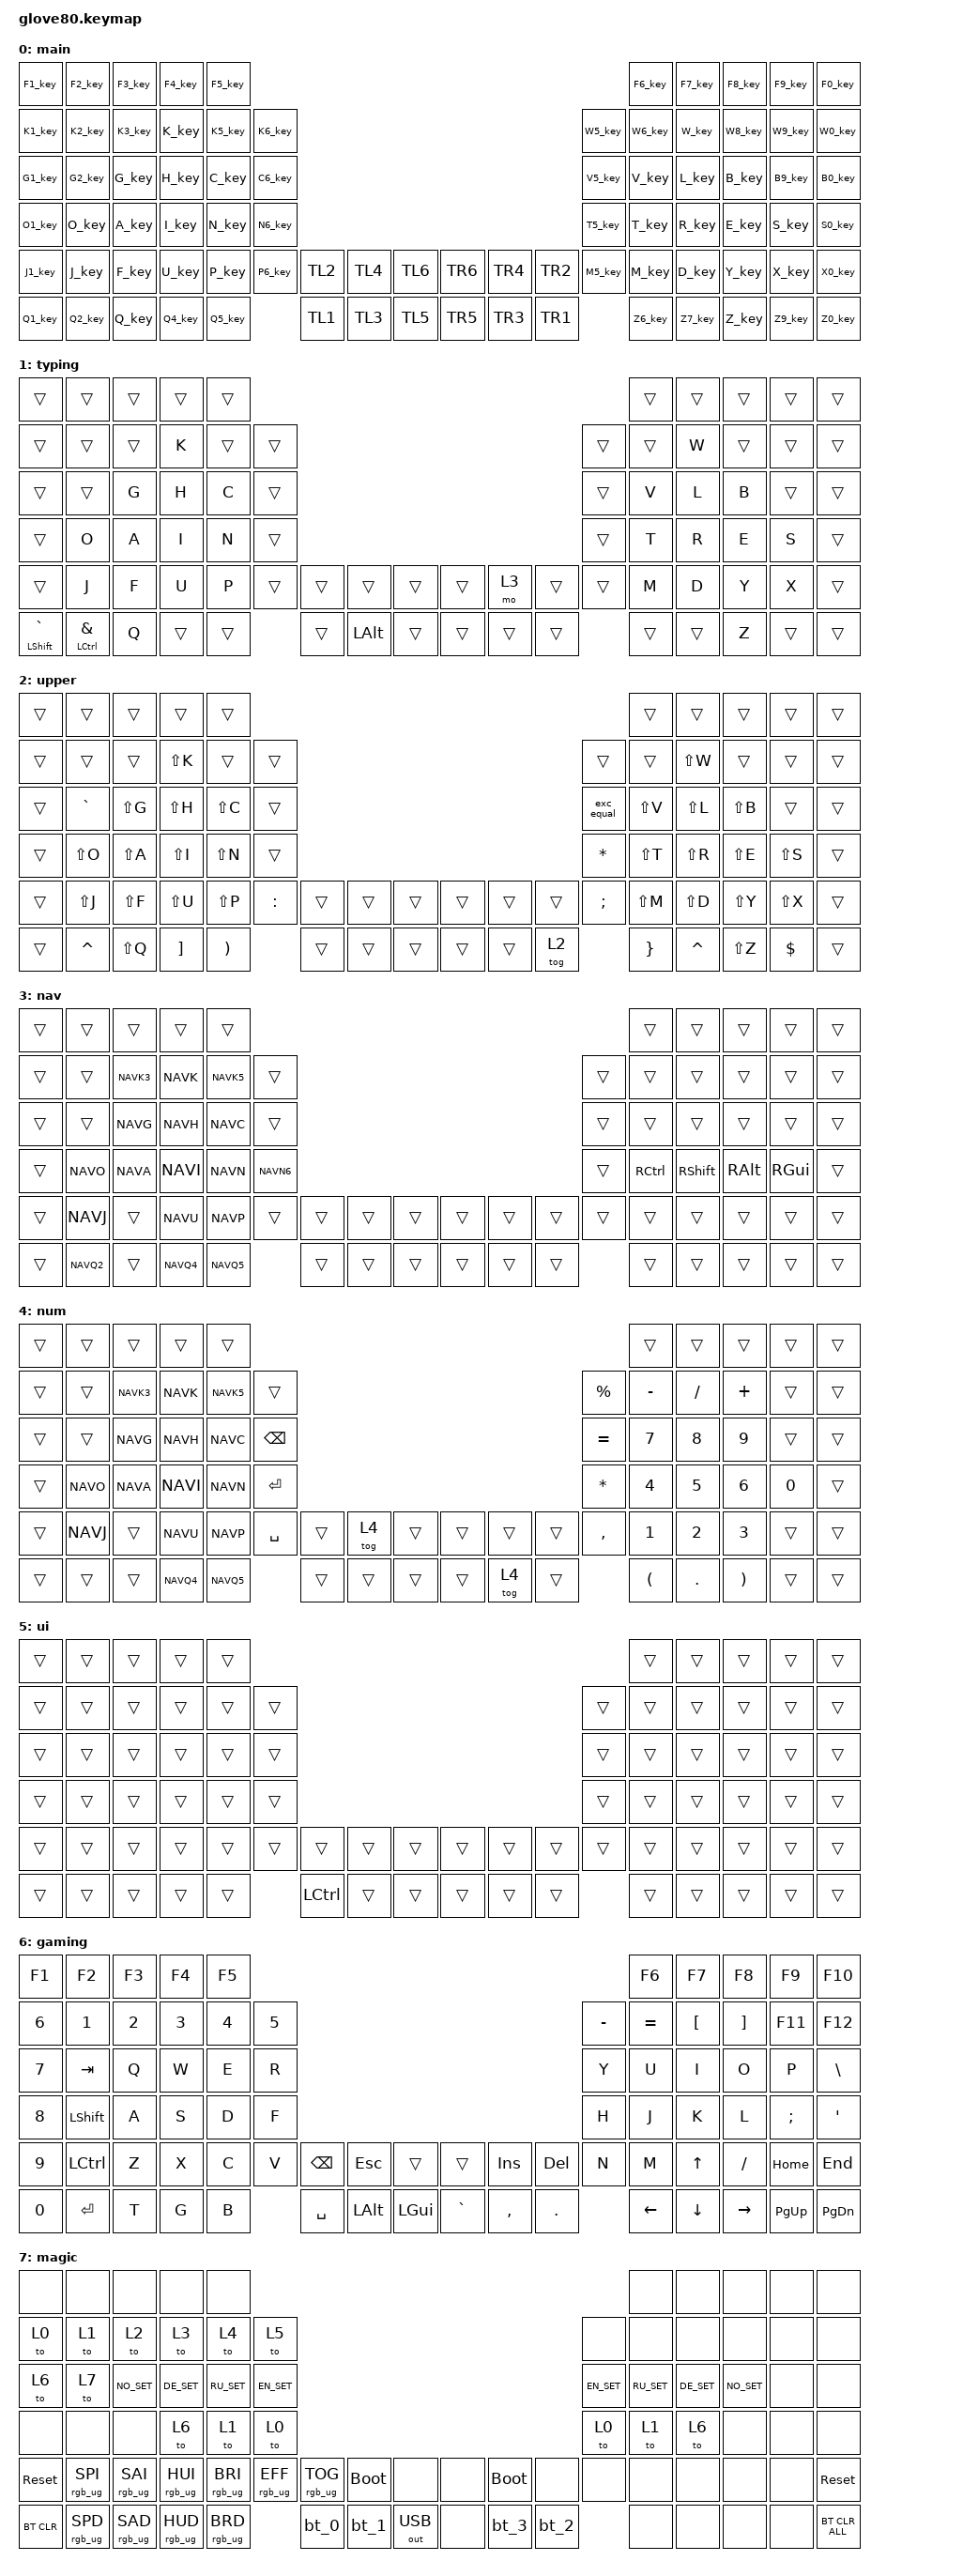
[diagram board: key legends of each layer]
/*
* Copyright (c) 2020 The ZMK Contributors
* Copyright (c) 2023 Innaworks Development Limited, trading as MoErgo
*
* SPDX-License-Identifier: MIT
*/
/* THIS FILE WAS GENERATED BY GLOVE80 LAYOUT EDITOR
*
* This file was generated automatically. You may or may not want to
* edit it directly.
*/

#include <behaviors.dtsi>
#include <dt-bindings/zmk/bt.h>
#include <dt-bindings/zmk/keys.h>
#include <dt-bindings/zmk/outputs.h>
#include <dt-bindings/zmk/rgb.h>

/* Automatically generated layer name #define */

#define Layer_Main 0
#define Layer_NAV 1
#define Layer_FUN 2
#define Layer_NUM 3
#define Layer_Magic 4

/ {
    macros {
        rgb_ug_status_macro: rgb_ug_status_macro {
            label = "RGB_UG_STATUS";
            compatible = "zmk,behavior-macro";
            #binding-cells = <0>;
            bindings = <&rgb_ug RGB_STATUS>;
        };
    };
};

/ {
    #ifdef BT_DISC_CMD

	behaviors {
		bt_0: bt_0 {
			compatible = "zmk,behavior-tap-dance";
			label = "BT_0";
			#binding-cells = <0>;
			tapping-term-ms = <200>;
			bindings = <&bt_select_0>, <&bt BT_DISC 0>;
		};

		bt_1: bt_1 {
			compatible = "zmk,behavior-tap-dance";
			label = "BT_1";
			#binding-cells = <0>;
			tapping-term-ms = <200>;
			bindings = <&bt_select_1>, <&bt BT_DISC 1>;
		};

		bt_2: bt_2 {
			compatible = "zmk,behavior-tap-dance";
			label = "BT_2";
			#binding-cells = <0>;
			tapping-term-ms = <200>;
			bindings = <&bt_select_2>, <&bt BT_DISC 2>;
		};

		bt_3: bt_3 {
			compatible = "zmk,behavior-tap-dance";
			label = "BT_3";
			#binding-cells = <0>;
			tapping-term-ms = <200>;
			bindings = <&bt_select_3>, <&bt BT_DISC 3>;
		};
	};

	macros {
		bt_select_0: bt_select_0 {
			label = "BT_SELECT_0";
			compatible = "zmk,behavior-macro";
			#binding-cells = <0>;
			bindings = <&out OUT_BLE &bt BT_SEL 0>;
		};

		bt_select_1: bt_select_1 {
			label = "BT_SELECT_1";
			compatible = "zmk,behavior-macro";
			#binding-cells = <0>;
			bindings = <&out OUT_BLE &bt BT_SEL 1>;
		};

		bt_select_2: bt_select_2 {
			label = "BT_SELECT_2";
			compatible = "zmk,behavior-macro";
			#binding-cells = <0>;
			bindings = <&out OUT_BLE &bt BT_SEL 2>;
		};

		bt_select_3: bt_select_3 {
			label = "BT_SELECT_3";
			compatible = "zmk,behavior-macro";
			#binding-cells = <0>;
			bindings = <&out OUT_BLE &bt BT_SEL 3>;
		};
	};

    #else

	macros {
		bt_0: bt_0 {
			label = "BT_0";
			compatible = "zmk,behavior-macro";
			#binding-cells = <0>;
			bindings = <&out OUT_BLE &bt BT_SEL 0>;
		};

		bt_1: bt_1 {
			label = "BT_1";
			compatible = "zmk,behavior-macro";
			#binding-cells = <0>;
			bindings = <&out OUT_BLE &bt BT_SEL 1>;
		};

		bt_2: bt_2 {
			label = "BT_2";
			compatible = "zmk,behavior-macro";
			#binding-cells = <0>;
			bindings = <&out OUT_BLE &bt BT_SEL 2>;
		};

		bt_3: bt_3 {
			label = "BT_3";
			compatible = "zmk,behavior-macro";
			#binding-cells = <0>;
			bindings = <&out OUT_BLE &bt BT_SEL 3>;
		};
	};

    #endif
};

&sk {
	release-after-ms = <900>;// release after 0.6s
	quick-release;// no double capitalization when rolling keys
};

&sl {
	ignore-modifiers;// allow chording sticky mods & layers

release-after-ms = <5000>;};

&lt {
	flavor = "balanced";
	tapping-term-ms = <200>;
	quick-tap-ms = <175>;
};


/ {
	behaviors {
		magic: magic {
			compatible = "zmk,behavior-hold-tap";
			label = "MAGIC_HOLD_TAP";
			#binding-cells = <2>;
			flavor = "tap-preferred";
			tapping-term-ms = <200>;
			bindings = <&mo>, <&rgb_ug_status_macro>;
		};

		lm: lm {
            compatible = "zmk,behavior-macro-two-param";
            wait-ms = <0>;
            tap-ms = <0>;
            #binding-cells = <2>;
            bindings = <&macro_param_1to1>,<&macro_press>,<&mo MACRO_PLACEHOLDER &macro_param_2to1>,<&macro_press>,<&kp MACRO_PLACEHOLDER>,<&macro_pause_for_release>,<&macro_param_2to1>,<&macro_release>,<&kp MACRO_PLACEHOLDER &macro_param_1to1>,<&macro_release>,<&mo MACRO_PLACEHOLDER>;
        };

		hml: hml {
			compatible = "zmk,behavior-hold-tap";
			#binding-cells = <2>;
			flavor = "balanced";
			tapping-term-ms = <270>;
			quick-tap-ms = <175>;
			require-prior-idle-ms = <150>;
			bindings = <&kp>, <&kp>;

			hold-trigger-key-positions = <28 29 30 31 32 40 41 42 43 44 58 59 60 61 62 75 76 77 78 79 69 70 71 72 73 74>;
			hold-trigger-on-release;
		};

		hmr: hmr {
			compatible = "zmk,behavior-hold-tap";
			#binding-cells = <2>;
			flavor = "balanced";
			tapping-term-ms = <280>;
			quick-tap-ms = <175>;
			require-prior-idle-ms = <350>;
			bindings = <&kp>, <&kp>;

			hold-trigger-key-positions = <27 26 25 24 23 39 38 37 36 35 51 50 49 48 47 68 67 66 65 64 15 14 13 12 11 10 69 70 71 72 73 74>;
			hold-trigger-on-release;
		};

		hlctrl:hlctrl {
			compatible = "zmk,behavior-hold-tap";
			#binding-cells = <2>;
			bindings = <&kp>, <&kp>;

			flavor = "tap-preferred";
			tapping-term-ms = <220>;
			quick-tap-ms = <220>;
			hold-trigger-key-positions = <0>;
		};



		swapper: swapper {
			compatible = "zmk,behavior-tri-state";
			#binding-cells = <0>;
			bindings = <&kp TAB>;
			ignored-key-positions = <25>;
		};

		copy_cut: copy_cut {
			compatible = "zmk,behavior-tap-dance";
			#binding-cells = <0>;
			tapping-term-ms = <200>;
			bindings = <&kp LC(INS)>, <&kp LC(X)>;
		};

		amp_ctrl:amp_ctrl { label = "amp_ctrl"; #binding-cells = <2>; compatible = "zmk,behavior-hold-tap";
            flavor = "balanced"; hold-trigger-on-release; tapping-term-ms = <150>; quick-tap-ms = <175>; require-prior-idle-ms = <0>; hold-trigger-key-positions = <0 1 2 3 4 10 11 12 22 23 34 46 13 24 25 26 35 36 37 38 47 48 49 50 66 14 15 27 39 51 64 65 67 68 5 6 7 8 9 19 20 21 32 33 45 63 18 29 30 31 41 42 43 44 59 60 61 62 77 16 17 28 40 58 75 76 79 80>;
            bindings = <&kp>, <&kp>;
        };

        grave_shft:grave_shft { label = "grave_shft"; #binding-cells = <2>; compatible = "zmk,behavior-hold-tap";
            flavor = "balanced"; hold-trigger-on-release; tapping-term-ms = <150>; quick-tap-ms = <175>; require-prior-idle-ms = <0>; hold-trigger-key-positions = <0 1 2 3 4 10 11 12 22 23 34 46 13 24 25 26 35 36 37 38 47 48 49 50 66 14 15 27 39 51 64 65 67 68 5 6 7 8 9 19 20 21 32 33 45 63 18 29 30 31 41 42 43 44 59 60 61 62 77 16 17 28 40 58 75 76 79 80>;
            bindings = <&kp>, <&kp>;
        };


/*<macros-start>*/

        reloadkeymap: reloadkeymap { label = "RELOADKEYMAP"; #binding-cells = <0>; compatible = "zmk,behavior-macro"; 
            wait-ms = <0>; tap-ms = <0>;
            bindings = <&kp LA(K) &kp TAB &kp TAB &kp SPACE &kp SPACE>;
        };

        cut_line: cut_line { label = "CUT_LINE"; #binding-cells = <0>; compatible = "zmk,behavior-macro"; 
            wait-ms = <0>; tap-ms = <0>;
            bindings = <&select_line &kp K_CUT &kp DELETE>;
        };

        move_down: move_down { label = "MOVE_DOWN"; #binding-cells = <0>; compatible = "zmk,behavior-macro"; 
            wait-ms = <0>; tap-ms = <0>;
            bindings = <&cut_line &kp DOWN &kp K_PASTE>;
        };

        move_up: move_up { label = "MOVE_UP"; #binding-cells = <0>; compatible = "zmk,behavior-macro"; 
            wait-ms = <0>; tap-ms = <0>;
            bindings = <&cut_line &kp UP_ARROW &kp K_PASTE>;
        };

        select_word: select_word { label = "SELECT_WORD"; #binding-cells = <0>; compatible = "zmk,behavior-macro"; 
            wait-ms = <0>; tap-ms = <0>;
            bindings = <&select_word_right>, <&select_word_left>;
        };

        select_line: select_line { label = "SELECT_LINE"; #binding-cells = <0>; compatible = "zmk,behavior-macro"; 
            wait-ms = <0>; tap-ms = <0>;
            bindings = <&kp HOME &kp LS(END)>;
        };

        delete_word: delete_word { label = "DELETE_WORD"; #binding-cells = <0>; compatible = "zmk,behavior-macro"; 
            wait-ms = <0>; tap-ms = <0>;
            bindings = <&select_word &kp BACKSPACE>;
        };

        delete_line: delete_line { label = "DELETE_LINE"; #binding-cells = <0>; compatible = "zmk,behavior-macro"; 
            wait-ms = <0>; tap-ms = <0>;
            bindings = <&select_line &kp BACKSPACE &kp BACKSPACE>;
        };

        copy_line: copy_line { label = "COPY_LINE"; #binding-cells = <0>; compatible = "zmk,behavior-macro"; 
            wait-ms = <0>; tap-ms = <0>;
            bindings = <&kp HOME &kp LS(END) &kp LC(C) &kp LC(RIGHT)>;
        };

        select_word_right: select_word_right { label = "SELECT_WORD_RIGHT"; #binding-cells = <0>; compatible = "zmk,behavior-macro"; 
            wait-ms = <0>; tap-ms = <0>;
            bindings = <&kp LC(RIGHT) &kp LC(LEFT) &kp LC(LS(RIGHT))>;
        };

        select_word_left: select_word_left { label = "SELECT_WORD_LEFT"; #binding-cells = <0>; compatible = "zmk,behavior-macro"; 
            wait-ms = <0>; tap-ms = <0>;
            bindings = <&kp LC(LEFT) &kp LC(RIGHT) &kp LC(LS(LEFT))>;
        };

        duplicate_line: duplicate_line { label = "DUPLICATE_LINE"; #binding-cells = <0>; compatible = "zmk,behavior-macro"; 
            wait-ms = <0>; tap-ms = <0>;
            bindings = <&kp HOME &kp LS(END) &kp LC(C) &kp RIGHT &kp ENTER &kp LC(V)>;
        };

        mo_ui: mo_ui { label = "MO_UI"; #binding-cells = <1>; compatible = "zmk,behavior-macro-one-param"; 
            wait-ms = <0>; tap-ms = <0>;
            bindings = <&macro_press>,<&mo 5 &macro_param_1to1>,<&macro_press>,<&kp MACRO_PLACEHOLDER>,<&macro_pause_for_release>,<&macro_param_1to1>,<&macro_release>,<&kp MACRO_PLACEHOLDER>,<&macro_release>,<&mo 5>,<&macro_press>;
        };

        exc_equal: exc_equal { label = "EXC_EQUAL"; #binding-cells = <0>; compatible = "zmk,behavior-macro"; 
            wait-ms = <0>; tap-ms = <0>;
            bindings = <&macro_tap>, <&kp EXCLAMATION>, <&kp EQUAL>;
        };

        grave_grave_grave: grave_grave_grave { label = "GRAVE_GRAVE_GRAVE"; #binding-cells = <0>; compatible = "zmk,behavior-macro"; 
            wait-ms = <0>; tap-ms = <0>;
            bindings = <&macro_tap>, <&kp GRAVE>, <&kp GRAVE>, <&kp GRAVE>;
        };
/*<macros-end>*/



/*<mods-start>*/

        H_key_hold_tap:H_key_hold_tap { label = "H_KEY_HOLD_TAP"; #binding-cells = <2>; compatible = "zmk,behavior-hold-tap";  
            flavor = "balanced"; hold-trigger-on-release; tapping-term-ms = <280>; quick-tap-ms = <175>; require-prior-idle-ms = <200>; hold-trigger-key-positions = <26 24 38>;
            bindings = <&mo_ui>, <&kp>;
        };

        A_key_hold_tap:A_key_hold_tap { label = "A_KEY_HOLD_TAP"; #binding-cells = <2>; compatible = "zmk,behavior-hold-tap";  
            flavor = "balanced"; hold-trigger-on-release; tapping-term-ms = <280>; quick-tap-ms = <175>; require-prior-idle-ms = <200>; hold-trigger-key-positions = <5 6 7 8 9 19 20 21 32 33 45 63 18 29 30 31 41 42 43 44 59 60 61 62 77 16 17 28 40 58 75 76 79 80>;
            bindings = <&kp>, <&kp>;
        };

        I_key_hold_tap:I_key_hold_tap { label = "I_KEY_HOLD_TAP"; #binding-cells = <2>; compatible = "zmk,behavior-hold-tap";  
            flavor = "balanced"; hold-trigger-on-release; tapping-term-ms = <280>; quick-tap-ms = <175>; require-prior-idle-ms = <200>; hold-trigger-key-positions = <24 26 36 38 48 50 18 5 6 7 8 9 19 20 21 32 33 45 63 18 29 30 31 41 42 43 44 59 60 61 62 77 16 17 28 40 58 75 76 79 80>;
            bindings = <&kp>, <&kp>;
        };

        N_key_hold_tap:N_key_hold_tap { label = "N_KEY_HOLD_TAP"; #binding-cells = <2>; compatible = "zmk,behavior-hold-tap";  
            flavor = "balanced"; hold-trigger-on-release; tapping-term-ms = <280>; quick-tap-ms = <175>; require-prior-idle-ms = <200>; hold-trigger-key-positions = <0 1 2 3 4 10 11 12 22 23 34 46 13 24 25 26 35 36 37 38 47 48 49 50 66 14 15 27 39 51 64 65 67 68 5 6 7 8 9 19 20 21 32 33 45 63 18 29 30 31 41 42 43 44 59 60 61 62 77 16 17 28 40 58 75 76 79 80>;
            bindings = <&kp>, <&kp>;
        };

        F_key_hold_tap:F_key_hold_tap { label = "F_KEY_HOLD_TAP"; #binding-cells = <2>; compatible = "zmk,behavior-hold-tap";  
            flavor = "balanced"; hold-trigger-on-release; tapping-term-ms = <280>; quick-tap-ms = <175>; require-prior-idle-ms = <200>; hold-trigger-key-positions = <25 26 50 38 5 6 7 8 9 19 20 21 32 33 45 63 18 29 30 31 41 42 43 44 59 60 61 62 77 16 17 28 40 58 75 76 79 80>;
            bindings = <&mo>, <&kp>;
        };

        grave_x_gra_gra_gra:grave_x_gra_gra_gra { label = "GRAVE_X_GRA_GRA_GRA"; #binding-cells = <2>; compatible = "zmk,behavior-hold-tap";  
            flavor = "balanced"; hold-trigger-on-release; tapping-term-ms = <250>; quick-tap-ms = <175>; require-prior-idle-ms = <0>; hold-trigger-key-positions = <0 1 2 3 4 10 11 12 22 23 34 46 13 24 25 26 35 36 37 38 47 48 49 50 66 14 15 27 39 51 64 65 67 68 5 6 7 8 9 19 20 21 32 33 45 63 18 29 30 31 41 42 43 44 59 60 61 62 77 16 17 28 40 58 75 76 79 80>;
            bindings = <&grave_grave_grave>, <&kp>;
        };

        lef_bra_x_rig_bra:lef_bra_x_rig_bra { label = "LEF_BRA_X_RIG_BRA"; #binding-cells = <2>; compatible = "zmk,behavior-hold-tap";  
            flavor = "balanced"; hold-trigger-on-release; tapping-term-ms = <250>; quick-tap-ms = <175>; require-prior-idle-ms = <0>; hold-trigger-key-positions = <0 1 2 3 4 10 11 12 22 23 34 46 13 24 25 26 35 36 37 38 47 48 49 50 66 14 15 27 39 51 64 65 67 68 5 6 7 8 9 19 20 21 32 33 45 63 18 29 30 31 41 42 43 44 59 60 61 62 77 16 17 28 40 58 75 76 79 80>;
            bindings = <&kp>, <&kp>;
        };

        lef_par_x_rig_par:lef_par_x_rig_par { label = "LEF_PAR_X_RIG_PAR"; #binding-cells = <2>; compatible = "zmk,behavior-hold-tap";  
            flavor = "balanced"; hold-trigger-on-release; tapping-term-ms = <250>; quick-tap-ms = <175>; require-prior-idle-ms = <0>; hold-trigger-key-positions = <0 1 2 3 4 10 11 12 22 23 34 46 13 24 25 26 35 36 37 38 47 48 49 50 66 14 15 27 39 51 64 65 67 68 5 6 7 8 9 19 20 21 32 33 45 63 18 29 30 31 41 42 43 44 59 60 61 62 77 16 17 28 40 58 75 76 79 80>;
            bindings = <&kp>, <&kp>;
        };

        T_key_hold_tap:T_key_hold_tap { label = "T_KEY_HOLD_TAP"; #binding-cells = <2>; compatible = "zmk,behavior-hold-tap";  
            flavor = "balanced"; hold-trigger-on-release; tapping-term-ms = <280>; quick-tap-ms = <175>; require-prior-idle-ms = <200>; hold-trigger-key-positions = <0 1 2 3 4 10 11 12 22 23 34 46 13 24 25 26 35 36 37 38 47 48 49 50 66 14 15 27 39 51 64 65 67 68 5 6 7 8 9 19 20 21 32 33 45 63 18 29 30 31 41 42 43 44 59 60 61 62 77 16 17 28 40 58 75 76 79 80>;
            bindings = <&kp>, <&kp>;
        };

        R_key_hold_tap:R_key_hold_tap { label = "R_KEY_HOLD_TAP"; #binding-cells = <2>; compatible = "zmk,behavior-hold-tap";  
            flavor = "balanced"; hold-trigger-on-release; tapping-term-ms = <280>; quick-tap-ms = <175>; require-prior-idle-ms = <200>; hold-trigger-key-positions = <0 1 2 3 4 10 11 12 22 23 34 46 13 24 25 26 35 36 37 38 47 48 49 50 66 14 15 27 39 51 64 65 67 68>;
            bindings = <&kp>, <&kp>;
        };

        E_key_hold_tap:E_key_hold_tap { label = "E_KEY_HOLD_TAP"; #binding-cells = <2>; compatible = "zmk,behavior-hold-tap";  
            flavor = "balanced"; hold-trigger-on-release; tapping-term-ms = <280>; quick-tap-ms = <175>; require-prior-idle-ms = <200>; hold-trigger-key-positions = <0 1 2 3 4 10 11 12 22 23 34 46 13 24 25 26 35 36 37 38 47 48 49 50 66 14 15 27 39 51 64 65 67 68>;
            bindings = <&kp>, <&kp>;
        };

        left_brace_x_rig_bra:left_brace_x_rig_bra { label = "LEFT_BRACE_X_RIG_BRA"; #binding-cells = <2>; compatible = "zmk,behavior-hold-tap";  
            flavor = "balanced"; hold-trigger-on-release; tapping-term-ms = <280>; quick-tap-ms = <175>; require-prior-idle-ms = <0>; hold-trigger-key-positions = <0 1 2 3 4 10 11 12 22 23 34 46 13 24 25 26 35 36 37 38 47 48 49 50 66 14 15 27 39 51 64 65 67 68 5 6 7 8 9 19 20 21 32 33 45 63 18 29 30 31 41 42 43 44 59 60 61 62 77 16 17 28 40 58 75 76 79 80>;
            bindings = <&kp>, <&kp>;
        };

        EN_SET:EN_SET { label = "EN_SET"; compatible = "zmk,behavior-mod-morph"; #binding-cells = <0>;
            bindings = <&kp LG(F10)>, <&kp LG(F10)>;
            mods = <(MOD_LALT|MOD_LCTL|MOD_LGUI|MOD_LSFT|MOD_RALT|MOD_RCTL|MOD_RGUI|MOD_RSFT)>;
            keep-mods = <(MOD_LALT|MOD_LCTL|MOD_LGUI|MOD_LSFT|MOD_RALT|MOD_RCTL|MOD_RGUI|MOD_RSFT)>;
        };

        RU_SET:RU_SET { label = "RU_SET"; compatible = "zmk,behavior-mod-morph"; #binding-cells = <0>;
            bindings = <&kp LG(F11)>, <&kp LG(F11)>;
            mods = <(MOD_LALT|MOD_LCTL|MOD_LGUI|MOD_LSFT|MOD_RALT|MOD_RCTL|MOD_RGUI|MOD_RSFT)>;
            keep-mods = <(MOD_LALT|MOD_LCTL|MOD_LGUI|MOD_LSFT|MOD_RALT|MOD_RCTL|MOD_RGUI|MOD_RSFT)>;
        };

        DE_SET:DE_SET { label = "DE_SET"; compatible = "zmk,behavior-mod-morph"; #binding-cells = <0>;
            bindings = <&kp LG(F12)>, <&kp LG(F12)>;
            mods = <(MOD_LALT|MOD_LCTL|MOD_LGUI|MOD_LSFT|MOD_RALT|MOD_RCTL|MOD_RGUI|MOD_RSFT)>;
            keep-mods = <(MOD_LALT|MOD_LCTL|MOD_LGUI|MOD_LSFT|MOD_RALT|MOD_RCTL|MOD_RGUI|MOD_RSFT)>;
        };

        NO_SET:NO_SET { label = "NO_SET"; compatible = "zmk,behavior-mod-morph"; #binding-cells = <0>;
            bindings = <&kp LG(F13)>, <&kp LG(F13)>;
            mods = <(MOD_LALT|MOD_LCTL|MOD_LGUI|MOD_LSFT|MOD_RALT|MOD_RCTL|MOD_RGUI|MOD_RSFT)>;
            keep-mods = <(MOD_LALT|MOD_LCTL|MOD_LGUI|MOD_LSFT|MOD_RALT|MOD_RCTL|MOD_RGUI|MOD_RSFT)>;
        };

        NAVK3:NAVK3 { label = "NAVK3"; compatible = "zmk,behavior-mod-morph"; #binding-cells = <0>;
            bindings = <&none>, <&none>;
            mods = <(MOD_LALT|MOD_LCTL|MOD_LGUI|MOD_LSFT|MOD_RALT|MOD_RCTL|MOD_RGUI|MOD_RSFT)>;
            keep-mods = <(MOD_LALT|MOD_LCTL|MOD_LGUI|MOD_LSFT|MOD_RALT|MOD_RCTL|MOD_RGUI|MOD_RSFT)>;
        };

        NAVK:NAVK { label = "NAVK"; compatible = "zmk,behavior-mod-morph"; #binding-cells = <0>;
            bindings = <&kp PAGE_UP>, <&kp PAGE_UP>;
            mods = <(MOD_LALT|MOD_LCTL|MOD_LGUI|MOD_LSFT|MOD_RALT|MOD_RCTL|MOD_RGUI|MOD_RSFT)>;
            keep-mods = <(MOD_LALT|MOD_LCTL|MOD_LGUI|MOD_LSFT|MOD_RALT|MOD_RCTL|MOD_RGUI|MOD_RSFT)>;
        };

        NAVK5:NAVK5 { label = "NAVK5"; compatible = "zmk,behavior-mod-morph"; #binding-cells = <0>;
            bindings = <&kp PAGE_DOWN>, <&kp PAGE_DOWN>;
            mods = <(MOD_LALT|MOD_LCTL|MOD_LGUI|MOD_LSFT|MOD_RALT|MOD_RCTL|MOD_RGUI|MOD_RSFT)>;
            keep-mods = <(MOD_LALT|MOD_LCTL|MOD_LGUI|MOD_LSFT|MOD_RALT|MOD_RCTL|MOD_RGUI|MOD_RSFT)>;
        };

        NAVG:NAVG { label = "NAVG"; compatible = "zmk,behavior-mod-morph"; #binding-cells = <0>;
            bindings = <&none>, <&none>;
            mods = <(MOD_LALT|MOD_LCTL|MOD_LGUI|MOD_LSFT|MOD_RALT|MOD_RCTL|MOD_RGUI|MOD_RSFT)>;
            keep-mods = <(MOD_LALT|MOD_LCTL|MOD_LGUI|MOD_LSFT|MOD_RALT|MOD_RCTL|MOD_RGUI|MOD_RSFT)>;
        };

        NAVH:NAVH { label = "NAVH"; compatible = "zmk,behavior-mod-morph"; #binding-cells = <0>;
            bindings = <&kp HOME>, <&kp HOME>;
            mods = <(MOD_LALT|MOD_LCTL|MOD_LGUI|MOD_LSFT|MOD_RALT|MOD_RCTL|MOD_RGUI|MOD_RSFT)>;
            keep-mods = <(MOD_LALT|MOD_LCTL|MOD_LGUI|MOD_LSFT|MOD_RALT|MOD_RCTL|MOD_RGUI|MOD_RSFT)>;
        };

        NAVC:NAVC { label = "NAVC"; compatible = "zmk,behavior-mod-morph"; #binding-cells = <0>;
            bindings = <&kp END>, <&kp END>;
            mods = <(MOD_LALT|MOD_LCTL|MOD_LGUI|MOD_LSFT|MOD_RALT|MOD_RCTL|MOD_RGUI|MOD_RSFT)>;
            keep-mods = <(MOD_LALT|MOD_LCTL|MOD_LGUI|MOD_LSFT|MOD_RALT|MOD_RCTL|MOD_RGUI|MOD_RSFT)>;
        };

        NAVO:NAVO { label = "NAVO"; compatible = "zmk,behavior-mod-morph"; #binding-cells = <0>;
            bindings = <&kp LSHIFT>, <&kp LSHIFT>;
            mods = <(MOD_LALT|MOD_LCTL|MOD_LGUI|MOD_LSFT|MOD_RALT|MOD_RCTL|MOD_RGUI|MOD_RSFT)>;
            keep-mods = <(MOD_LALT|MOD_LCTL|MOD_LGUI|MOD_LSFT|MOD_RALT|MOD_RCTL|MOD_RGUI|MOD_RSFT)>;
        };

        NAVA:NAVA { label = "NAVA"; compatible = "zmk,behavior-mod-morph"; #binding-cells = <0>;
            bindings = <&none>, <&none>;
            mods = <(MOD_LALT|MOD_LCTL|MOD_LGUI|MOD_LSFT|MOD_RALT|MOD_RCTL|MOD_RGUI|MOD_RSFT)>;
            keep-mods = <(MOD_LALT|MOD_LCTL|MOD_LGUI|MOD_LSFT|MOD_RALT|MOD_RCTL|MOD_RGUI|MOD_RSFT)>;
        };

        NAVI:NAVI { label = "NAVI"; compatible = "zmk,behavior-mod-morph"; #binding-cells = <0>;
            bindings = <&kp LC(LEFT)>, <&kp LC(LEFT)>;
            mods = <(MOD_LALT|MOD_LCTL|MOD_LGUI|MOD_LSFT|MOD_RALT|MOD_RCTL|MOD_RGUI|MOD_RSFT)>;
            keep-mods = <(MOD_LALT|MOD_LCTL|MOD_LGUI|MOD_LSFT|MOD_RALT|MOD_RCTL|MOD_RGUI|MOD_RSFT)>;
        };

        NAVN:NAVN { label = "NAVN"; compatible = "zmk,behavior-mod-morph"; #binding-cells = <0>;
            bindings = <&kp LC(RIGHT)>, <&kp LC(RIGHT)>;
            mods = <(MOD_LALT|MOD_LCTL|MOD_LGUI|MOD_LSFT|MOD_RALT|MOD_RCTL|MOD_RGUI|MOD_RSFT)>;
            keep-mods = <(MOD_LALT|MOD_LCTL|MOD_LGUI|MOD_LSFT|MOD_RALT|MOD_RCTL|MOD_RGUI|MOD_RSFT)>;
        };

        NAVN6:NAVN6 { label = "NAVN6"; compatible = "zmk,behavior-mod-morph"; #binding-cells = <0>;
            bindings = <&kp TAB>, <&kp TAB>;
            mods = <(MOD_LALT|MOD_LCTL|MOD_LGUI|MOD_LSFT|MOD_RALT|MOD_RCTL|MOD_RGUI|MOD_RSFT)>;
            keep-mods = <(MOD_LALT|MOD_LCTL|MOD_LGUI|MOD_LSFT|MOD_RALT|MOD_RCTL|MOD_RGUI|MOD_RSFT)>;
        };

        NAVJ:NAVJ { label = "NAVJ"; compatible = "zmk,behavior-mod-morph"; #binding-cells = <0>;
            bindings = <&kp LCTRL>, <&kp LCTRL>;
            mods = <(MOD_LALT|MOD_LCTL|MOD_LGUI|MOD_LSFT|MOD_RALT|MOD_RCTL|MOD_RGUI|MOD_RSFT)>;
            keep-mods = <(MOD_LALT|MOD_LCTL|MOD_LGUI|MOD_LSFT|MOD_RALT|MOD_RCTL|MOD_RGUI|MOD_RSFT)>;
        };

        NAVU:NAVU { label = "NAVU"; compatible = "zmk,behavior-mod-morph"; #binding-cells = <0>;
            bindings = <&kp UP>, <&kp UP>;
            mods = <(MOD_LALT|MOD_LCTL|MOD_LGUI|MOD_LSFT|MOD_RALT|MOD_RCTL|MOD_RGUI|MOD_RSFT)>;
            keep-mods = <(MOD_LALT|MOD_LCTL|MOD_LGUI|MOD_LSFT|MOD_RALT|MOD_RCTL|MOD_RGUI|MOD_RSFT)>;
        };

        NAVP:NAVP { label = "NAVP"; compatible = "zmk,behavior-mod-morph"; #binding-cells = <0>;
            bindings = <&kp DOWN>, <&kp DOWN>;
            mods = <(MOD_LALT|MOD_LCTL|MOD_LGUI|MOD_LSFT|MOD_RALT|MOD_RCTL|MOD_RGUI|MOD_RSFT)>;
            keep-mods = <(MOD_LALT|MOD_LCTL|MOD_LGUI|MOD_LSFT|MOD_RALT|MOD_RCTL|MOD_RGUI|MOD_RSFT)>;
        };

        NAVQ2:NAVQ2 { label = "NAVQ2"; compatible = "zmk,behavior-mod-morph"; #binding-cells = <0>;
            bindings = <&kp DELETE>, <&kp DELETE>;
            mods = <(MOD_LALT|MOD_LCTL|MOD_LGUI|MOD_LSFT|MOD_RALT|MOD_RCTL|MOD_RGUI|MOD_RSFT)>;
            keep-mods = <(MOD_LALT|MOD_LCTL|MOD_LGUI|MOD_LSFT|MOD_RALT|MOD_RCTL|MOD_RGUI|MOD_RSFT)>;
        };

        NAVQ4:NAVQ4 { label = "NAVQ4"; compatible = "zmk,behavior-mod-morph"; #binding-cells = <0>;
            bindings = <&kp LEFT>, <&kp LEFT>;
            mods = <(MOD_LALT|MOD_LCTL|MOD_LGUI|MOD_LSFT|MOD_RALT|MOD_RCTL|MOD_RGUI|MOD_RSFT)>;
            keep-mods = <(MOD_LALT|MOD_LCTL|MOD_LGUI|MOD_LSFT|MOD_RALT|MOD_RCTL|MOD_RGUI|MOD_RSFT)>;
        };

        NAVQ5:NAVQ5 { label = "NAVQ5"; compatible = "zmk,behavior-mod-morph"; #binding-cells = <0>;
            bindings = <&kp RIGHT>, <&kp RIGHT>;
            mods = <(MOD_LALT|MOD_LCTL|MOD_LGUI|MOD_LSFT|MOD_RALT|MOD_RCTL|MOD_RGUI|MOD_RSFT)>;
            keep-mods = <(MOD_LALT|MOD_LCTL|MOD_LGUI|MOD_LSFT|MOD_RALT|MOD_RCTL|MOD_RGUI|MOD_RSFT)>;
        };

        F1_key:F1_key { label = "F1_KEY"; compatible = "zmk,behavior-mod-morph"; #binding-cells = <0>;
            bindings = <&kp F1>, <&kp F1>;
            mods = <(MOD_LALT|MOD_LCTL|MOD_LGUI|MOD_LSFT|MOD_RALT|MOD_RCTL|MOD_RGUI|MOD_RSFT)>;
            keep-mods = <(MOD_LALT|MOD_LCTL|MOD_LGUI|MOD_LSFT|MOD_RALT|MOD_RCTL|MOD_RGUI|MOD_RSFT)>;
        };

        F2_key:F2_key { label = "F2_KEY"; compatible = "zmk,behavior-mod-morph"; #binding-cells = <0>;
            bindings = <&kp F2>, <&kp F2>;
            mods = <(MOD_LALT|MOD_LCTL|MOD_LGUI|MOD_LSFT|MOD_RALT|MOD_RCTL|MOD_RGUI|MOD_RSFT)>;
            keep-mods = <(MOD_LALT|MOD_LCTL|MOD_LGUI|MOD_LSFT|MOD_RALT|MOD_RCTL|MOD_RGUI|MOD_RSFT)>;
        };

        F3_key:F3_key { label = "F3_KEY"; compatible = "zmk,behavior-mod-morph"; #binding-cells = <0>;
            bindings = <&kp F3>, <&kp F3>;
            mods = <(MOD_LALT|MOD_LCTL|MOD_LGUI|MOD_LSFT|MOD_RALT|MOD_RCTL|MOD_RGUI|MOD_RSFT)>;
            keep-mods = <(MOD_LALT|MOD_LCTL|MOD_LGUI|MOD_LSFT|MOD_RALT|MOD_RCTL|MOD_RGUI|MOD_RSFT)>;
        };

        F4_key:F4_key { label = "F4_KEY"; compatible = "zmk,behavior-mod-morph"; #binding-cells = <0>;
            bindings = <&kp F4>, <&kp F4>;
            mods = <(MOD_LALT|MOD_LCTL|MOD_LGUI|MOD_LSFT|MOD_RALT|MOD_RCTL|MOD_RGUI|MOD_RSFT)>;
            keep-mods = <(MOD_LALT|MOD_LCTL|MOD_LGUI|MOD_LSFT|MOD_RALT|MOD_RCTL|MOD_RGUI|MOD_RSFT)>;
        };

        F5_key:F5_key { label = "F5_KEY"; compatible = "zmk,behavior-mod-morph"; #binding-cells = <0>;
            bindings = <&kp F5>, <&kp F5>;
            mods = <(MOD_LALT|MOD_LCTL|MOD_LGUI|MOD_LSFT|MOD_RALT|MOD_RCTL|MOD_RGUI|MOD_RSFT)>;
            keep-mods = <(MOD_LALT|MOD_LCTL|MOD_LGUI|MOD_LSFT|MOD_RALT|MOD_RCTL|MOD_RGUI|MOD_RSFT)>;
        };

        K1_key:K1_key { label = "K1_KEY"; compatible = "zmk,behavior-mod-morph"; #binding-cells = <0>;
            bindings = <&kp F11>, <&kp F11>;
            mods = <(MOD_LALT|MOD_LCTL|MOD_LGUI|MOD_LSFT|MOD_RALT|MOD_RCTL|MOD_RGUI|MOD_RSFT)>;
            keep-mods = <(MOD_LALT|MOD_LCTL|MOD_LGUI|MOD_LSFT|MOD_RALT|MOD_RCTL|MOD_RGUI|MOD_RSFT)>;
        };

        K2_key:K2_key { label = "K2_KEY"; compatible = "zmk,behavior-mod-morph"; #binding-cells = <0>;
            bindings = <&kp F12>, <&kp F12>;
            mods = <(MOD_LALT|MOD_LCTL|MOD_LGUI|MOD_LSFT|MOD_RALT|MOD_RCTL|MOD_RGUI|MOD_RSFT)>;
            keep-mods = <(MOD_LALT|MOD_LCTL|MOD_LGUI|MOD_LSFT|MOD_RALT|MOD_RCTL|MOD_RGUI|MOD_RSFT)>;
        };

        G1_key:G1_key { label = "G1_KEY"; compatible = "zmk,behavior-mod-morph"; #binding-cells = <0>;
            bindings = <&G1_key_lshift_link>, <&G1_key_rshift_sink>;
            mods = <(MOD_RSFT)>;
            
        };

        G1_key_lshift_link:G1_key_lshift_link { label = "G1_KEY_LSHIFT_LINK"; compatible = "zmk,behavior-mod-morph"; #binding-cells = <0>;
            bindings = <&kp DOLLAR>, <&G1_key_lshift_sink>;
            mods = <(MOD_LSFT)>;
            
        };

        G1_key_lshift_sink:G1_key_lshift_sink { label = "G1_KEY_LSHIFT_SINK"; compatible = "zmk,behavior-mod-morph"; #binding-cells = <0>;
            bindings = <&kp LA(F13)>, <&kp DOLLAR>;
            mods = <(MOD_LALT|MOD_LCTL|MOD_LGUI|MOD_RALT|MOD_RCTL|MOD_RGUI|MOD_RSFT)>;
            keep-mods = <(MOD_LALT|MOD_LCTL|MOD_LGUI|MOD_RALT|MOD_RCTL|MOD_RGUI|MOD_RSFT)>;
        };

        G1_key_rshift_sink:G1_key_rshift_sink { label = "G1_KEY_RSHIFT_SINK"; compatible = "zmk,behavior-mod-morph"; #binding-cells = <0>;
            bindings = <&kp RA(F13)>, <&kp DOLLAR>;
            mods = <(MOD_LALT|MOD_LCTL|MOD_LGUI|MOD_LSFT|MOD_RALT|MOD_RCTL|MOD_RGUI)>;
            keep-mods = <(MOD_LALT|MOD_LCTL|MOD_LGUI|MOD_LSFT|MOD_RALT|MOD_RCTL|MOD_RGUI)>;
        };

        G2_key:G2_key { label = "G2_KEY"; compatible = "zmk,behavior-mod-morph"; #binding-cells = <0>;
            bindings = <&G2_key_lshift_link>, <&G2_key_rshift_sink>;
            mods = <(MOD_RSFT)>;
            
        };

        G2_key_lshift_link:G2_key_lshift_link { label = "G2_KEY_LSHIFT_LINK"; compatible = "zmk,behavior-mod-morph"; #binding-cells = <0>;
            bindings = <&kp HASH>, <&G2_key_lshift_sink>;
            mods = <(MOD_LSFT)>;
            
        };

        G2_key_lshift_sink:G2_key_lshift_sink { label = "G2_KEY_LSHIFT_SINK"; compatible = "zmk,behavior-mod-morph"; #binding-cells = <0>;
            bindings = <&kp LA(F14)>, <&kp HASH>;
            mods = <(MOD_LALT|MOD_LCTL|MOD_LGUI|MOD_RALT|MOD_RCTL|MOD_RGUI|MOD_RSFT)>;
            keep-mods = <(MOD_LALT|MOD_LCTL|MOD_LGUI|MOD_RALT|MOD_RCTL|MOD_RGUI|MOD_RSFT)>;
        };

        G2_key_rshift_sink:G2_key_rshift_sink { label = "G2_KEY_RSHIFT_SINK"; compatible = "zmk,behavior-mod-morph"; #binding-cells = <0>;
            bindings = <&kp RA(F14)>, <&kp HASH>;
            mods = <(MOD_LALT|MOD_LCTL|MOD_LGUI|MOD_LSFT|MOD_RALT|MOD_RCTL|MOD_RGUI)>;
            keep-mods = <(MOD_LALT|MOD_LCTL|MOD_LGUI|MOD_LSFT|MOD_RALT|MOD_RCTL|MOD_RGUI)>;
        };

        O1_key:O1_key { label = "O1_KEY"; compatible = "zmk,behavior-mod-morph"; #binding-cells = <0>;
            bindings = <&O1_key_lshift_link>, <&O1_key_rshift_sink>;
            mods = <(MOD_RSFT)>;
            
        };

        O1_key_lshift_link:O1_key_lshift_link { label = "O1_KEY_LSHIFT_LINK"; compatible = "zmk,behavior-mod-morph"; #binding-cells = <0>;
            bindings = <&kp DOUBLE_QUOTES>, <&O1_key_lshift_sink>;
            mods = <(MOD_LSFT)>;
            
        };

        O1_key_lshift_sink:O1_key_lshift_sink { label = "O1_KEY_LSHIFT_SINK"; compatible = "zmk,behavior-mod-morph"; #binding-cells = <0>;
            bindings = <&kp LA(F15)>, <&kp DOUBLE_QUOTES>;
            mods = <(MOD_LALT|MOD_LCTL|MOD_LGUI|MOD_RALT|MOD_RCTL|MOD_RGUI|MOD_RSFT)>;
            keep-mods = <(MOD_LALT|MOD_LCTL|MOD_LGUI|MOD_RALT|MOD_RCTL|MOD_RGUI|MOD_RSFT)>;
        };

        O1_key_rshift_sink:O1_key_rshift_sink { label = "O1_KEY_RSHIFT_SINK"; compatible = "zmk,behavior-mod-morph"; #binding-cells = <0>;
            bindings = <&kp RA(F15)>, <&kp DOUBLE_QUOTES>;
            mods = <(MOD_LALT|MOD_LCTL|MOD_LGUI|MOD_LSFT|MOD_RALT|MOD_RCTL|MOD_RGUI)>;
            keep-mods = <(MOD_LALT|MOD_LCTL|MOD_LGUI|MOD_LSFT|MOD_RALT|MOD_RCTL|MOD_RGUI)>;
        };

        J1_key:J1_key { label = "J1_KEY"; compatible = "zmk,behavior-mod-morph"; #binding-cells = <0>;
            bindings = <&J1_key_lshift_link>, <&J1_key_rshift_sink>;
            mods = <(MOD_RSFT)>;
            
        };

        J1_key_lshift_link:J1_key_lshift_link { label = "J1_KEY_LSHIFT_LINK"; compatible = "zmk,behavior-mod-morph"; #binding-cells = <0>;
            bindings = <&kp SINGLE_QUOTE>, <&J1_key_lshift_sink>;
            mods = <(MOD_LSFT)>;
            
        };

        J1_key_lshift_sink:J1_key_lshift_sink { label = "J1_KEY_LSHIFT_SINK"; compatible = "zmk,behavior-mod-morph"; #binding-cells = <0>;
            bindings = <&kp LA(F16)>, <&kp SINGLE_QUOTE>;
            mods = <(MOD_LALT|MOD_LCTL|MOD_LGUI|MOD_RALT|MOD_RCTL|MOD_RGUI|MOD_RSFT)>;
            keep-mods = <(MOD_LALT|MOD_LCTL|MOD_LGUI|MOD_RALT|MOD_RCTL|MOD_RGUI|MOD_RSFT)>;
        };

        J1_key_rshift_sink:J1_key_rshift_sink { label = "J1_KEY_RSHIFT_SINK"; compatible = "zmk,behavior-mod-morph"; #binding-cells = <0>;
            bindings = <&kp RA(F16)>, <&kp SINGLE_QUOTE>;
            mods = <(MOD_LALT|MOD_LCTL|MOD_LGUI|MOD_LSFT|MOD_RALT|MOD_RCTL|MOD_RGUI)>;
            keep-mods = <(MOD_LALT|MOD_LCTL|MOD_LGUI|MOD_LSFT|MOD_RALT|MOD_RCTL|MOD_RGUI)>;
        };

        K_key:K_key { label = "K_KEY"; compatible = "zmk,behavior-mod-morph"; #binding-cells = <0>;
            bindings = <&K_key_rshift_link>, <&K_key_lctrl_sink>;
            mods = <(MOD_LCTL)>;
            
        };

        K_key_lshift_link:K_key_lshift_link { label = "K_KEY_LSHIFT_LINK"; compatible = "zmk,behavior-mod-morph"; #binding-cells = <0>;
            bindings = <&kp K>, <&K_key_lshift_sink>;
            mods = <(MOD_LSFT)>;
            
        };

        K_key_rshift_link:K_key_rshift_link { label = "K_KEY_RSHIFT_LINK"; compatible = "zmk,behavior-mod-morph"; #binding-cells = <0>;
            bindings = <&K_key_lshift_link>, <&K_key_rshift_sink>;
            mods = <(MOD_RSFT)>;
            
        };

        K_key_lshift_sink:K_key_lshift_sink { label = "K_KEY_LSHIFT_SINK"; compatible = "zmk,behavior-mod-morph"; #binding-cells = <0>;
            bindings = <&kp LS(F1)>, <&kp K>;
            mods = <(MOD_LALT|MOD_LCTL|MOD_LGUI|MOD_RALT|MOD_RCTL|MOD_RGUI|MOD_RSFT)>;
            keep-mods = <(MOD_LALT|MOD_LCTL|MOD_LGUI|MOD_RALT|MOD_RCTL|MOD_RGUI|MOD_RSFT)>;
        };

        K_key_rshift_sink:K_key_rshift_sink { label = "K_KEY_RSHIFT_SINK"; compatible = "zmk,behavior-mod-morph"; #binding-cells = <0>;
            bindings = <&kp RS(F1)>, <&kp K>;
            mods = <(MOD_LALT|MOD_LCTL|MOD_LGUI|MOD_LSFT|MOD_RALT|MOD_RCTL|MOD_RGUI)>;
            keep-mods = <(MOD_LALT|MOD_LCTL|MOD_LGUI|MOD_LSFT|MOD_RALT|MOD_RCTL|MOD_RGUI)>;
        };

        K_key_lctrl_sink:K_key_lctrl_sink { label = "K_KEY_LCTRL_SINK"; compatible = "zmk,behavior-mod-morph"; #binding-cells = <0>;
            bindings = <&kp LC(F1)>, <&kp K>;
            mods = <(MOD_LALT|MOD_LGUI|MOD_LSFT|MOD_RALT|MOD_RCTL|MOD_RGUI|MOD_RSFT)>;
            keep-mods = <(MOD_LALT|MOD_LGUI|MOD_LSFT|MOD_RALT|MOD_RCTL|MOD_RGUI|MOD_RSFT)>;
        };

        G_key:G_key { label = "G_KEY"; compatible = "zmk,behavior-mod-morph"; #binding-cells = <0>;
            bindings = <&G_key_rshift_link>, <&G_key_lctrl_sink>;
            mods = <(MOD_LCTL)>;
            
        };

        G_key_lshift_link:G_key_lshift_link { label = "G_KEY_LSHIFT_LINK"; compatible = "zmk,behavior-mod-morph"; #binding-cells = <0>;
            bindings = <&kp G>, <&G_key_lshift_sink>;
            mods = <(MOD_LSFT)>;
            
        };

        G_key_rshift_link:G_key_rshift_link { label = "G_KEY_RSHIFT_LINK"; compatible = "zmk,behavior-mod-morph"; #binding-cells = <0>;
            bindings = <&G_key_lshift_link>, <&G_key_rshift_sink>;
            mods = <(MOD_RSFT)>;
            
        };

        G_key_lshift_sink:G_key_lshift_sink { label = "G_KEY_LSHIFT_SINK"; compatible = "zmk,behavior-mod-morph"; #binding-cells = <0>;
            bindings = <&kp LC(X)>, <&kp G>;
            mods = <(MOD_LALT|MOD_LCTL|MOD_LGUI|MOD_RALT|MOD_RCTL|MOD_RGUI|MOD_RSFT)>;
            keep-mods = <(MOD_LALT|MOD_LCTL|MOD_LGUI|MOD_RALT|MOD_RCTL|MOD_RGUI|MOD_RSFT)>;
        };

        G_key_rshift_sink:G_key_rshift_sink { label = "G_KEY_RSHIFT_SINK"; compatible = "zmk,behavior-mod-morph"; #binding-cells = <0>;
            bindings = <&kp RS(F2)>, <&kp G>;
            mods = <(MOD_LALT|MOD_LCTL|MOD_LGUI|MOD_LSFT|MOD_RALT|MOD_RCTL|MOD_RGUI)>;
            keep-mods = <(MOD_LALT|MOD_LCTL|MOD_LGUI|MOD_LSFT|MOD_RALT|MOD_RCTL|MOD_RGUI)>;
        };

        G_key_lctrl_sink:G_key_lctrl_sink { label = "G_KEY_LCTRL_SINK"; compatible = "zmk,behavior-mod-morph"; #binding-cells = <0>;
            bindings = <&kp LC(F2)>, <&kp G>;
            mods = <(MOD_LALT|MOD_LGUI|MOD_LSFT|MOD_RALT|MOD_RCTL|MOD_RGUI|MOD_RSFT)>;
            keep-mods = <(MOD_LALT|MOD_LGUI|MOD_LSFT|MOD_RALT|MOD_RCTL|MOD_RGUI|MOD_RSFT)>;
        };

        H_key:H_key { label = "H_KEY"; compatible = "zmk,behavior-mod-morph"; #binding-cells = <0>;
            bindings = <&H_key_rshift_link>, <&H_key_lctrl_sink>;
            mods = <(MOD_LCTL)>;
            
        };

        H_key_lshift_link:H_key_lshift_link { label = "H_KEY_LSHIFT_LINK"; compatible = "zmk,behavior-mod-morph"; #binding-cells = <0>;
            bindings = <&H_key_hold_tap LS(LA(LGUI)) H>, <&H_key_lshift_sink>;
            mods = <(MOD_LSFT)>;
            
        };

        H_key_rshift_link:H_key_rshift_link { label = "H_KEY_RSHIFT_LINK"; compatible = "zmk,behavior-mod-morph"; #binding-cells = <0>;
            bindings = <&H_key_lshift_link>, <&H_key_rshift_sink>;
            mods = <(MOD_RSFT)>;
            
        };

        H_key_lshift_sink:H_key_lshift_sink { label = "H_KEY_LSHIFT_SINK"; compatible = "zmk,behavior-mod-morph"; #binding-cells = <0>;
            bindings = <&kp LS(F3)>, <&H_key_hold_tap LS(LA(LGUI)) H>;
            mods = <(MOD_LALT|MOD_LCTL|MOD_LGUI|MOD_RALT|MOD_RCTL|MOD_RGUI|MOD_RSFT)>;
            keep-mods = <(MOD_LALT|MOD_LCTL|MOD_LGUI|MOD_RALT|MOD_RCTL|MOD_RGUI|MOD_RSFT)>;
        };

        H_key_rshift_sink:H_key_rshift_sink { label = "H_KEY_RSHIFT_SINK"; compatible = "zmk,behavior-mod-morph"; #binding-cells = <0>;
            bindings = <&kp RS(F3)>, <&H_key_hold_tap LS(LA(LGUI)) H>;
            mods = <(MOD_LALT|MOD_LCTL|MOD_LGUI|MOD_LSFT|MOD_RALT|MOD_RCTL|MOD_RGUI)>;
            keep-mods = <(MOD_LALT|MOD_LCTL|MOD_LGUI|MOD_LSFT|MOD_RALT|MOD_RCTL|MOD_RGUI)>;
        };

        H_key_lctrl_sink:H_key_lctrl_sink { label = "H_KEY_LCTRL_SINK"; compatible = "zmk,behavior-mod-morph"; #binding-cells = <0>;
            bindings = <&kp LC(F3)>, <&H_key_hold_tap LS(LA(LGUI)) H>;
            mods = <(MOD_LALT|MOD_LGUI|MOD_LSFT|MOD_RALT|MOD_RCTL|MOD_RGUI|MOD_RSFT)>;
            keep-mods = <(MOD_LALT|MOD_LGUI|MOD_LSFT|MOD_RALT|MOD_RCTL|MOD_RGUI|MOD_RSFT)>;
        };

        C_key:C_key { label = "C_KEY"; compatible = "zmk,behavior-mod-morph"; #binding-cells = <0>;
            bindings = <&C_key_lctrl_link>, <&C_key_rctrl_sink>;
            mods = <(MOD_RCTL)>;
            
        };

        C_key_lshift_link:C_key_lshift_link { label = "C_KEY_LSHIFT_LINK"; compatible = "zmk,behavior-mod-morph"; #binding-cells = <0>;
            bindings = <&kp C>, <&C_key_lshift_sink>;
            mods = <(MOD_LSFT)>;
            
        };

        C_key_rshift_link:C_key_rshift_link { label = "C_KEY_RSHIFT_LINK"; compatible = "zmk,behavior-mod-morph"; #binding-cells = <0>;
            bindings = <&C_key_lshift_link>, <&C_key_rshift_sink>;
            mods = <(MOD_RSFT)>;
            
        };

        C_key_lctrl_link:C_key_lctrl_link { label = "C_KEY_LCTRL_LINK"; compatible = "zmk,behavior-mod-morph"; #binding-cells = <0>;
            bindings = <&C_key_rshift_link>, <&C_key_lctrl_sink>;
            mods = <(MOD_LCTL)>;
            
        };

        C_key_lshift_sink:C_key_lshift_sink { label = "C_KEY_LSHIFT_SINK"; compatible = "zmk,behavior-mod-morph"; #binding-cells = <0>;
            bindings = <&kp LC(C)>, <&kp C>;
            mods = <(MOD_LALT|MOD_LCTL|MOD_LGUI|MOD_RALT|MOD_RCTL|MOD_RGUI|MOD_RSFT)>;
            keep-mods = <(MOD_LALT|MOD_LCTL|MOD_LGUI|MOD_RALT|MOD_RCTL|MOD_RGUI|MOD_RSFT)>;
        };

        C_key_rshift_sink:C_key_rshift_sink { label = "C_KEY_RSHIFT_SINK"; compatible = "zmk,behavior-mod-morph"; #binding-cells = <0>;
            bindings = <&kp RS(F4)>, <&kp C>;
            mods = <(MOD_LALT|MOD_LCTL|MOD_LGUI|MOD_LSFT|MOD_RALT|MOD_RCTL|MOD_RGUI)>;
            keep-mods = <(MOD_LALT|MOD_LCTL|MOD_LGUI|MOD_LSFT|MOD_RALT|MOD_RCTL|MOD_RGUI)>;
        };

        C_key_lctrl_sink:C_key_lctrl_sink { label = "C_KEY_LCTRL_SINK"; compatible = "zmk,behavior-mod-morph"; #binding-cells = <0>;
            bindings = <&kp LC(F4)>, <&kp C>;
            mods = <(MOD_LALT|MOD_LGUI|MOD_LSFT|MOD_RALT|MOD_RCTL|MOD_RGUI|MOD_RSFT)>;
            keep-mods = <(MOD_LALT|MOD_LGUI|MOD_LSFT|MOD_RALT|MOD_RCTL|MOD_RGUI|MOD_RSFT)>;
        };

        C_key_rctrl_sink:C_key_rctrl_sink { label = "C_KEY_RCTRL_SINK"; compatible = "zmk,behavior-mod-morph"; #binding-cells = <0>;
            bindings = <&kp RC(F4)>, <&kp C>;
            mods = <(MOD_LALT|MOD_LCTL|MOD_LGUI|MOD_LSFT|MOD_RALT|MOD_RGUI|MOD_RSFT)>;
            keep-mods = <(MOD_LALT|MOD_LCTL|MOD_LGUI|MOD_LSFT|MOD_RALT|MOD_RGUI|MOD_RSFT)>;
        };

        O_key:O_key { label = "O_KEY"; compatible = "zmk,behavior-mod-morph"; #binding-cells = <0>;
            bindings = <&O_key_rshift_link>, <&O_key_lctrl_sink>;
            mods = <(MOD_LCTL)>;
            
        };

        O_key_lshift_link:O_key_lshift_link { label = "O_KEY_LSHIFT_LINK"; compatible = "zmk,behavior-mod-morph"; #binding-cells = <0>;
            bindings = <&kp O>, <&O_key_lshift_sink>;
            mods = <(MOD_LSFT)>;
            
        };

        O_key_rshift_link:O_key_rshift_link { label = "O_KEY_RSHIFT_LINK"; compatible = "zmk,behavior-mod-morph"; #binding-cells = <0>;
            bindings = <&O_key_lshift_link>, <&O_key_rshift_sink>;
            mods = <(MOD_RSFT)>;
            
        };

        O_key_lshift_sink:O_key_lshift_sink { label = "O_KEY_LSHIFT_SINK"; compatible = "zmk,behavior-mod-morph"; #binding-cells = <0>;
            bindings = <&kp LS(F6)>, <&kp O>;
            mods = <(MOD_LALT|MOD_LCTL|MOD_LGUI|MOD_RALT|MOD_RCTL|MOD_RGUI|MOD_RSFT)>;
            keep-mods = <(MOD_LALT|MOD_LCTL|MOD_LGUI|MOD_RALT|MOD_RCTL|MOD_RGUI|MOD_RSFT)>;
        };

        O_key_rshift_sink:O_key_rshift_sink { label = "O_KEY_RSHIFT_SINK"; compatible = "zmk,behavior-mod-morph"; #binding-cells = <0>;
            bindings = <&kp RS(F6)>, <&kp O>;
            mods = <(MOD_LALT|MOD_LCTL|MOD_LGUI|MOD_LSFT|MOD_RALT|MOD_RCTL|MOD_RGUI)>;
            keep-mods = <(MOD_LALT|MOD_LCTL|MOD_LGUI|MOD_LSFT|MOD_RALT|MOD_RCTL|MOD_RGUI)>;
        };

        O_key_lctrl_sink:O_key_lctrl_sink { label = "O_KEY_LCTRL_SINK"; compatible = "zmk,behavior-mod-morph"; #binding-cells = <0>;
            bindings = <&kp LC(F6)>, <&kp O>;
            mods = <(MOD_LALT|MOD_LGUI|MOD_LSFT|MOD_RALT|MOD_RCTL|MOD_RGUI|MOD_RSFT)>;
            keep-mods = <(MOD_LALT|MOD_LGUI|MOD_LSFT|MOD_RALT|MOD_RCTL|MOD_RGUI|MOD_RSFT)>;
        };

        A_key:A_key { label = "A_KEY"; compatible = "zmk,behavior-mod-morph"; #binding-cells = <0>;
            bindings = <&A_key_lctrl_link>, <&A_key_rctrl_sink>;
            mods = <(MOD_RCTL)>;
            
        };

        A_key_lshift_link:A_key_lshift_link { label = "A_KEY_LSHIFT_LINK"; compatible = "zmk,behavior-mod-morph"; #binding-cells = <0>;
            bindings = <&A_key_hold_tap LALT A>, <&A_key_lshift_sink>;
            mods = <(MOD_LSFT)>;
            
        };

        A_key_rshift_link:A_key_rshift_link { label = "A_KEY_RSHIFT_LINK"; compatible = "zmk,behavior-mod-morph"; #binding-cells = <0>;
            bindings = <&A_key_lshift_link>, <&A_key_rshift_sink>;
            mods = <(MOD_RSFT)>;
            
        };

        A_key_lctrl_link:A_key_lctrl_link { label = "A_KEY_LCTRL_LINK"; compatible = "zmk,behavior-mod-morph"; #binding-cells = <0>;
            bindings = <&A_key_rshift_link>, <&A_key_lctrl_sink>;
            mods = <(MOD_LCTL)>;
            
        };

        A_key_lshift_sink:A_key_lshift_sink { label = "A_KEY_LSHIFT_SINK"; compatible = "zmk,behavior-mod-morph"; #binding-cells = <0>;
            bindings = <&kp LC(Z)>, <&A_key_hold_tap LALT A>;
            mods = <(MOD_LALT|MOD_LCTL|MOD_LGUI|MOD_RALT|MOD_RCTL|MOD_RGUI|MOD_RSFT)>;
            keep-mods = <(MOD_LALT|MOD_LCTL|MOD_LGUI|MOD_RALT|MOD_RCTL|MOD_RGUI|MOD_RSFT)>;
        };

        A_key_rshift_sink:A_key_rshift_sink { label = "A_KEY_RSHIFT_SINK"; compatible = "zmk,behavior-mod-morph"; #binding-cells = <0>;
            bindings = <&kp RS(F7)>, <&A_key_hold_tap LALT A>;
            mods = <(MOD_LALT|MOD_LCTL|MOD_LGUI|MOD_LSFT|MOD_RALT|MOD_RCTL|MOD_RGUI)>;
            keep-mods = <(MOD_LALT|MOD_LCTL|MOD_LGUI|MOD_LSFT|MOD_RALT|MOD_RCTL|MOD_RGUI)>;
        };

        A_key_lctrl_sink:A_key_lctrl_sink { label = "A_KEY_LCTRL_SINK"; compatible = "zmk,behavior-mod-morph"; #binding-cells = <0>;
            bindings = <&kp LC(F7)>, <&A_key_hold_tap LALT A>;
            mods = <(MOD_LALT|MOD_LGUI|MOD_LSFT|MOD_RALT|MOD_RCTL|MOD_RGUI|MOD_RSFT)>;
            keep-mods = <(MOD_LALT|MOD_LGUI|MOD_LSFT|MOD_RALT|MOD_RCTL|MOD_RGUI|MOD_RSFT)>;
        };

        A_key_rctrl_sink:A_key_rctrl_sink { label = "A_KEY_RCTRL_SINK"; compatible = "zmk,behavior-mod-morph"; #binding-cells = <0>;
            bindings = <&kp RC(F7)>, <&A_key_hold_tap LALT A>;
            mods = <(MOD_LALT|MOD_LCTL|MOD_LGUI|MOD_LSFT|MOD_RALT|MOD_RGUI|MOD_RSFT)>;
            keep-mods = <(MOD_LALT|MOD_LCTL|MOD_LGUI|MOD_LSFT|MOD_RALT|MOD_RGUI|MOD_RSFT)>;
        };

        I_key:I_key { label = "I_KEY"; compatible = "zmk,behavior-mod-morph"; #binding-cells = <0>;
            bindings = <&I_key_rshift_link>, <&I_key_lctrl_sink>;
            mods = <(MOD_LCTL)>;
            
        };

        I_key_lshift_link:I_key_lshift_link { label = "I_KEY_LSHIFT_LINK"; compatible = "zmk,behavior-mod-morph"; #binding-cells = <0>;
            bindings = <&I_key_hold_tap LSHIFT I>, <&I_key_lshift_sink>;
            mods = <(MOD_LSFT)>;
            
        };

        I_key_rshift_link:I_key_rshift_link { label = "I_KEY_RSHIFT_LINK"; compatible = "zmk,behavior-mod-morph"; #binding-cells = <0>;
            bindings = <&I_key_lshift_link>, <&I_key_rshift_sink>;
            mods = <(MOD_RSFT)>;
            
        };

        I_key_lshift_sink:I_key_lshift_sink { label = "I_KEY_LSHIFT_SINK"; compatible = "zmk,behavior-mod-morph"; #binding-cells = <0>;
            bindings = <&kp LS(F8)>, <&I_key_hold_tap LSHIFT I>;
            mods = <(MOD_LALT|MOD_LCTL|MOD_LGUI|MOD_RALT|MOD_RCTL|MOD_RGUI|MOD_RSFT)>;
            keep-mods = <(MOD_LALT|MOD_LCTL|MOD_LGUI|MOD_RALT|MOD_RCTL|MOD_RGUI|MOD_RSFT)>;
        };

        I_key_rshift_sink:I_key_rshift_sink { label = "I_KEY_RSHIFT_SINK"; compatible = "zmk,behavior-mod-morph"; #binding-cells = <0>;
            bindings = <&kp RS(F8)>, <&I_key_hold_tap LSHIFT I>;
            mods = <(MOD_LALT|MOD_LCTL|MOD_LGUI|MOD_LSFT|MOD_RALT|MOD_RCTL|MOD_RGUI)>;
            keep-mods = <(MOD_LALT|MOD_LCTL|MOD_LGUI|MOD_LSFT|MOD_RALT|MOD_RCTL|MOD_RGUI)>;
        };

        I_key_lctrl_sink:I_key_lctrl_sink { label = "I_KEY_LCTRL_SINK"; compatible = "zmk,behavior-mod-morph"; #binding-cells = <0>;
            bindings = <&kp LC(F8)>, <&I_key_hold_tap LSHIFT I>;
            mods = <(MOD_LALT|MOD_LGUI|MOD_LSFT|MOD_RALT|MOD_RCTL|MOD_RGUI|MOD_RSFT)>;
            keep-mods = <(MOD_LALT|MOD_LGUI|MOD_LSFT|MOD_RALT|MOD_RCTL|MOD_RGUI|MOD_RSFT)>;
        };

        N_key:N_key { label = "N_KEY"; compatible = "zmk,behavior-mod-morph"; #binding-cells = <0>;
            bindings = <&N_key_rshift_link>, <&N_key_lctrl_sink>;
            mods = <(MOD_LCTL)>;
            
        };

        N_key_lshift_link:N_key_lshift_link { label = "N_KEY_LSHIFT_LINK"; compatible = "zmk,behavior-mod-morph"; #binding-cells = <0>;
            bindings = <&N_key_hold_tap LCTRL N>, <&N_key_lshift_sink>;
            mods = <(MOD_LSFT)>;
            
        };

        N_key_rshift_link:N_key_rshift_link { label = "N_KEY_RSHIFT_LINK"; compatible = "zmk,behavior-mod-morph"; #binding-cells = <0>;
            bindings = <&N_key_lshift_link>, <&N_key_rshift_sink>;
            mods = <(MOD_RSFT)>;
            
        };

        N_key_lshift_sink:N_key_lshift_sink { label = "N_KEY_LSHIFT_SINK"; compatible = "zmk,behavior-mod-morph"; #binding-cells = <0>;
            bindings = <&kp LC(S)>, <&N_key_hold_tap LCTRL N>;
            mods = <(MOD_LALT|MOD_LCTL|MOD_LGUI|MOD_RALT|MOD_RCTL|MOD_RGUI|MOD_RSFT)>;
            keep-mods = <(MOD_LALT|MOD_LCTL|MOD_LGUI|MOD_RALT|MOD_RCTL|MOD_RGUI|MOD_RSFT)>;
        };

        N_key_rshift_sink:N_key_rshift_sink { label = "N_KEY_RSHIFT_SINK"; compatible = "zmk,behavior-mod-morph"; #binding-cells = <0>;
            bindings = <&kp RS(F9)>, <&N_key_hold_tap LCTRL N>;
            mods = <(MOD_LALT|MOD_LCTL|MOD_LGUI|MOD_LSFT|MOD_RALT|MOD_RCTL|MOD_RGUI)>;
            keep-mods = <(MOD_LALT|MOD_LCTL|MOD_LGUI|MOD_LSFT|MOD_RALT|MOD_RCTL|MOD_RGUI)>;
        };

        N_key_lctrl_sink:N_key_lctrl_sink { label = "N_KEY_LCTRL_SINK"; compatible = "zmk,behavior-mod-morph"; #binding-cells = <0>;
            bindings = <&kp LC(F9)>, <&N_key_hold_tap LCTRL N>;
            mods = <(MOD_LALT|MOD_LGUI|MOD_LSFT|MOD_RALT|MOD_RCTL|MOD_RGUI|MOD_RSFT)>;
            keep-mods = <(MOD_LALT|MOD_LGUI|MOD_LSFT|MOD_RALT|MOD_RCTL|MOD_RGUI|MOD_RSFT)>;
        };

        J_key:J_key { label = "J_KEY"; compatible = "zmk,behavior-mod-morph"; #binding-cells = <0>;
            bindings = <&J_key_rshift_link>, <&J_key_lctrl_sink>;
            mods = <(MOD_LCTL)>;
            
        };

        J_key_lshift_link:J_key_lshift_link { label = "J_KEY_LSHIFT_LINK"; compatible = "zmk,behavior-mod-morph"; #binding-cells = <0>;
            bindings = <&kp J>, <&J_key_lshift_sink>;
            mods = <(MOD_LSFT)>;
            
        };

        J_key_rshift_link:J_key_rshift_link { label = "J_KEY_RSHIFT_LINK"; compatible = "zmk,behavior-mod-morph"; #binding-cells = <0>;
            bindings = <&J_key_lshift_link>, <&J_key_rshift_sink>;
            mods = <(MOD_RSFT)>;
            
        };

        J_key_lshift_sink:J_key_lshift_sink { label = "J_KEY_LSHIFT_SINK"; compatible = "zmk,behavior-mod-morph"; #binding-cells = <0>;
            bindings = <&kp LS(F10)>, <&kp J>;
            mods = <(MOD_LALT|MOD_LCTL|MOD_LGUI|MOD_RALT|MOD_RCTL|MOD_RGUI|MOD_RSFT)>;
            keep-mods = <(MOD_LALT|MOD_LCTL|MOD_LGUI|MOD_RALT|MOD_RCTL|MOD_RGUI|MOD_RSFT)>;
        };

        J_key_rshift_sink:J_key_rshift_sink { label = "J_KEY_RSHIFT_SINK"; compatible = "zmk,behavior-mod-morph"; #binding-cells = <0>;
            bindings = <&kp RS(F10)>, <&kp J>;
            mods = <(MOD_LALT|MOD_LCTL|MOD_LGUI|MOD_LSFT|MOD_RALT|MOD_RCTL|MOD_RGUI)>;
            keep-mods = <(MOD_LALT|MOD_LCTL|MOD_LGUI|MOD_LSFT|MOD_RALT|MOD_RCTL|MOD_RGUI)>;
        };

        J_key_lctrl_sink:J_key_lctrl_sink { label = "J_KEY_LCTRL_SINK"; compatible = "zmk,behavior-mod-morph"; #binding-cells = <0>;
            bindings = <&kp LC(F10)>, <&kp J>;
            mods = <(MOD_LALT|MOD_LGUI|MOD_LSFT|MOD_RALT|MOD_RCTL|MOD_RGUI|MOD_RSFT)>;
            keep-mods = <(MOD_LALT|MOD_LGUI|MOD_LSFT|MOD_RALT|MOD_RCTL|MOD_RGUI|MOD_RSFT)>;
        };

        F_key:F_key { label = "F_KEY"; compatible = "zmk,behavior-mod-morph"; #binding-cells = <0>;
            bindings = <&F_key_lctrl_link>, <&F_key_rctrl_sink>;
            mods = <(MOD_RCTL)>;
            
        };

        F_key_lshift_link:F_key_lshift_link { label = "F_KEY_LSHIFT_LINK"; compatible = "zmk,behavior-mod-morph"; #binding-cells = <0>;
            bindings = <&F_key_hold_tap 3 F>, <&F_key_lshift_sink>;
            mods = <(MOD_LSFT)>;
            
        };

        F_key_rshift_link:F_key_rshift_link { label = "F_KEY_RSHIFT_LINK"; compatible = "zmk,behavior-mod-morph"; #binding-cells = <0>;
            bindings = <&F_key_lshift_link>, <&F_key_rshift_sink>;
            mods = <(MOD_RSFT)>;
            
        };

        F_key_lctrl_link:F_key_lctrl_link { label = "F_KEY_LCTRL_LINK"; compatible = "zmk,behavior-mod-morph"; #binding-cells = <0>;
            bindings = <&F_key_rshift_link>, <&F_key_lctrl_sink>;
            mods = <(MOD_LCTL)>;
            
        };

        F_key_lshift_sink:F_key_lshift_sink { label = "F_KEY_LSHIFT_SINK"; compatible = "zmk,behavior-mod-morph"; #binding-cells = <0>;
            bindings = <&kp LC(F)>, <&F_key_hold_tap 3 F>;
            mods = <(MOD_LALT|MOD_LCTL|MOD_LGUI|MOD_RALT|MOD_RCTL|MOD_RGUI|MOD_RSFT)>;
            keep-mods = <(MOD_LALT|MOD_LCTL|MOD_LGUI|MOD_RALT|MOD_RCTL|MOD_RGUI|MOD_RSFT)>;
        };

        F_key_rshift_sink:F_key_rshift_sink { label = "F_KEY_RSHIFT_SINK"; compatible = "zmk,behavior-mod-morph"; #binding-cells = <0>;
            bindings = <&kp RS(F11)>, <&F_key_hold_tap 3 F>;
            mods = <(MOD_LALT|MOD_LCTL|MOD_LGUI|MOD_LSFT|MOD_RALT|MOD_RCTL|MOD_RGUI)>;
            keep-mods = <(MOD_LALT|MOD_LCTL|MOD_LGUI|MOD_LSFT|MOD_RALT|MOD_RCTL|MOD_RGUI)>;
        };

        F_key_lctrl_sink:F_key_lctrl_sink { label = "F_KEY_LCTRL_SINK"; compatible = "zmk,behavior-mod-morph"; #binding-cells = <0>;
            bindings = <&kp LC(F11)>, <&F_key_hold_tap 3 F>;
            mods = <(MOD_LALT|MOD_LGUI|MOD_LSFT|MOD_RALT|MOD_RCTL|MOD_RGUI|MOD_RSFT)>;
            keep-mods = <(MOD_LALT|MOD_LGUI|MOD_LSFT|MOD_RALT|MOD_RCTL|MOD_RGUI|MOD_RSFT)>;
        };

        F_key_rctrl_sink:F_key_rctrl_sink { label = "F_KEY_RCTRL_SINK"; compatible = "zmk,behavior-mod-morph"; #binding-cells = <0>;
            bindings = <&kp RC(F11)>, <&F_key_hold_tap 3 F>;
            mods = <(MOD_LALT|MOD_LCTL|MOD_LGUI|MOD_LSFT|MOD_RALT|MOD_RGUI|MOD_RSFT)>;
            keep-mods = <(MOD_LALT|MOD_LCTL|MOD_LGUI|MOD_LSFT|MOD_RALT|MOD_RGUI|MOD_RSFT)>;
        };

        U_key:U_key { label = "U_KEY"; compatible = "zmk,behavior-mod-morph"; #binding-cells = <0>;
            bindings = <&U_key_rshift_link>, <&U_key_lctrl_sink>;
            mods = <(MOD_LCTL)>;
            
        };

        U_key_lshift_link:U_key_lshift_link { label = "U_KEY_LSHIFT_LINK"; compatible = "zmk,behavior-mod-morph"; #binding-cells = <0>;
            bindings = <&kp U>, <&U_key_lshift_sink>;
            mods = <(MOD_LSFT)>;
            
        };

        U_key_rshift_link:U_key_rshift_link { label = "U_KEY_RSHIFT_LINK"; compatible = "zmk,behavior-mod-morph"; #binding-cells = <0>;
            bindings = <&U_key_lshift_link>, <&U_key_rshift_sink>;
            mods = <(MOD_RSFT)>;
            
        };

        U_key_lshift_sink:U_key_lshift_sink { label = "U_KEY_LSHIFT_SINK"; compatible = "zmk,behavior-mod-morph"; #binding-cells = <0>;
            bindings = <&kp LS(F12)>, <&kp U>;
            mods = <(MOD_LALT|MOD_LCTL|MOD_LGUI|MOD_RALT|MOD_RCTL|MOD_RGUI|MOD_RSFT)>;
            keep-mods = <(MOD_LALT|MOD_LCTL|MOD_LGUI|MOD_RALT|MOD_RCTL|MOD_RGUI|MOD_RSFT)>;
        };

        U_key_rshift_sink:U_key_rshift_sink { label = "U_KEY_RSHIFT_SINK"; compatible = "zmk,behavior-mod-morph"; #binding-cells = <0>;
            bindings = <&kp RS(F12)>, <&kp U>;
            mods = <(MOD_LALT|MOD_LCTL|MOD_LGUI|MOD_LSFT|MOD_RALT|MOD_RCTL|MOD_RGUI)>;
            keep-mods = <(MOD_LALT|MOD_LCTL|MOD_LGUI|MOD_LSFT|MOD_RALT|MOD_RCTL|MOD_RGUI)>;
        };

        U_key_lctrl_sink:U_key_lctrl_sink { label = "U_KEY_LCTRL_SINK"; compatible = "zmk,behavior-mod-morph"; #binding-cells = <0>;
            bindings = <&kp LC(F12)>, <&kp U>;
            mods = <(MOD_LALT|MOD_LGUI|MOD_LSFT|MOD_RALT|MOD_RCTL|MOD_RGUI|MOD_RSFT)>;
            keep-mods = <(MOD_LALT|MOD_LGUI|MOD_LSFT|MOD_RALT|MOD_RCTL|MOD_RGUI|MOD_RSFT)>;
        };

        P_key:P_key { label = "P_KEY"; compatible = "zmk,behavior-mod-morph"; #binding-cells = <0>;
            bindings = <&P_key_rshift_link>, <&P_key_lctrl_sink>;
            mods = <(MOD_LCTL)>;
            
        };

        P_key_lshift_link:P_key_lshift_link { label = "P_KEY_LSHIFT_LINK"; compatible = "zmk,behavior-mod-morph"; #binding-cells = <0>;
            bindings = <&kp P>, <&P_key_lshift_sink>;
            mods = <(MOD_LSFT)>;
            
        };

        P_key_rshift_link:P_key_rshift_link { label = "P_KEY_RSHIFT_LINK"; compatible = "zmk,behavior-mod-morph"; #binding-cells = <0>;
            bindings = <&P_key_lshift_link>, <&P_key_rshift_sink>;
            mods = <(MOD_RSFT)>;
            
        };

        P_key_lshift_sink:P_key_lshift_sink { label = "P_KEY_LSHIFT_SINK"; compatible = "zmk,behavior-mod-morph"; #binding-cells = <0>;
            bindings = <&kp LC(V)>, <&kp P>;
            mods = <(MOD_LALT|MOD_LCTL|MOD_LGUI|MOD_RALT|MOD_RCTL|MOD_RGUI|MOD_RSFT)>;
            keep-mods = <(MOD_LALT|MOD_LCTL|MOD_LGUI|MOD_RALT|MOD_RCTL|MOD_RGUI|MOD_RSFT)>;
        };

        P_key_rshift_sink:P_key_rshift_sink { label = "P_KEY_RSHIFT_SINK"; compatible = "zmk,behavior-mod-morph"; #binding-cells = <0>;
            bindings = <&kp RS(F13)>, <&kp P>;
            mods = <(MOD_LALT|MOD_LCTL|MOD_LGUI|MOD_LSFT|MOD_RALT|MOD_RCTL|MOD_RGUI)>;
            keep-mods = <(MOD_LALT|MOD_LCTL|MOD_LGUI|MOD_LSFT|MOD_RALT|MOD_RCTL|MOD_RGUI)>;
        };

        P_key_lctrl_sink:P_key_lctrl_sink { label = "P_KEY_LCTRL_SINK"; compatible = "zmk,behavior-mod-morph"; #binding-cells = <0>;
            bindings = <&kp LC(F13)>, <&kp P>;
            mods = <(MOD_LALT|MOD_LGUI|MOD_LSFT|MOD_RALT|MOD_RCTL|MOD_RGUI|MOD_RSFT)>;
            keep-mods = <(MOD_LALT|MOD_LGUI|MOD_LSFT|MOD_RALT|MOD_RCTL|MOD_RGUI|MOD_RSFT)>;
        };

        Q_key:Q_key { label = "Q_KEY"; compatible = "zmk,behavior-mod-morph"; #binding-cells = <0>;
            bindings = <&Q_key_rshift_link>, <&Q_key_lctrl_sink>;
            mods = <(MOD_LCTL)>;
            
        };

        Q_key_lshift_link:Q_key_lshift_link { label = "Q_KEY_LSHIFT_LINK"; compatible = "zmk,behavior-mod-morph"; #binding-cells = <0>;
            bindings = <&kp Q>, <&Q_key_lshift_sink>;
            mods = <(MOD_LSFT)>;
            
        };

        Q_key_rshift_link:Q_key_rshift_link { label = "Q_KEY_RSHIFT_LINK"; compatible = "zmk,behavior-mod-morph"; #binding-cells = <0>;
            bindings = <&Q_key_lshift_link>, <&Q_key_rshift_sink>;
            mods = <(MOD_RSFT)>;
            
        };

        Q_key_lshift_sink:Q_key_lshift_sink { label = "Q_KEY_LSHIFT_SINK"; compatible = "zmk,behavior-mod-morph"; #binding-cells = <0>;
            bindings = <&kp LC(Y)>, <&kp Q>;
            mods = <(MOD_LALT|MOD_LCTL|MOD_LGUI|MOD_RALT|MOD_RCTL|MOD_RGUI|MOD_RSFT)>;
            keep-mods = <(MOD_LALT|MOD_LCTL|MOD_LGUI|MOD_RALT|MOD_RCTL|MOD_RGUI|MOD_RSFT)>;
        };

        Q_key_rshift_sink:Q_key_rshift_sink { label = "Q_KEY_RSHIFT_SINK"; compatible = "zmk,behavior-mod-morph"; #binding-cells = <0>;
            bindings = <&kp RS(PAUSE_BREAK)>, <&kp Q>;
            mods = <(MOD_LALT|MOD_LCTL|MOD_LGUI|MOD_LSFT|MOD_RALT|MOD_RCTL|MOD_RGUI)>;
            keep-mods = <(MOD_LALT|MOD_LCTL|MOD_LGUI|MOD_LSFT|MOD_RALT|MOD_RCTL|MOD_RGUI)>;
        };

        Q_key_lctrl_sink:Q_key_lctrl_sink { label = "Q_KEY_LCTRL_SINK"; compatible = "zmk,behavior-mod-morph"; #binding-cells = <0>;
            bindings = <&kp LC(PAUSE_BREAK)>, <&kp Q>;
            mods = <(MOD_LALT|MOD_LGUI|MOD_LSFT|MOD_RALT|MOD_RCTL|MOD_RGUI|MOD_RSFT)>;
            keep-mods = <(MOD_LALT|MOD_LGUI|MOD_LSFT|MOD_RALT|MOD_RCTL|MOD_RGUI|MOD_RSFT)>;
        };

        K3_key:K3_key { label = "K3_KEY"; compatible = "zmk,behavior-mod-morph"; #binding-cells = <0>;
            bindings = <&K3_key_lshift_link>, <&K3_key_rshift_sink>;
            mods = <(MOD_RSFT)>;
            
        };

        K3_key_lshift_link:K3_key_lshift_link { label = "K3_KEY_LSHIFT_LINK"; compatible = "zmk,behavior-mod-morph"; #binding-cells = <0>;
            bindings = <&kp BACKSLASH>, <&K3_key_lshift_sink>;
            mods = <(MOD_LSFT)>;
            
        };

        K3_key_lshift_sink:K3_key_lshift_sink { label = "K3_KEY_LSHIFT_SINK"; compatible = "zmk,behavior-mod-morph"; #binding-cells = <0>;
            bindings = <&kp LA(F17)>, <&kp BACKSLASH>;
            mods = <(MOD_LALT|MOD_LCTL|MOD_LGUI|MOD_RALT|MOD_RCTL|MOD_RGUI|MOD_RSFT)>;
            keep-mods = <(MOD_LALT|MOD_LCTL|MOD_LGUI|MOD_RALT|MOD_RCTL|MOD_RGUI|MOD_RSFT)>;
        };

        K3_key_rshift_sink:K3_key_rshift_sink { label = "K3_KEY_RSHIFT_SINK"; compatible = "zmk,behavior-mod-morph"; #binding-cells = <0>;
            bindings = <&kp RA(F17)>, <&kp BACKSLASH>;
            mods = <(MOD_LALT|MOD_LCTL|MOD_LGUI|MOD_LSFT|MOD_RALT|MOD_RCTL|MOD_RGUI)>;
            keep-mods = <(MOD_LALT|MOD_LCTL|MOD_LGUI|MOD_LSFT|MOD_RALT|MOD_RCTL|MOD_RGUI)>;
        };

        K5_key:K5_key { label = "K5_KEY"; compatible = "zmk,behavior-mod-morph"; #binding-cells = <0>;
            bindings = <&K5_key_lshift_link>, <&K5_key_rshift_sink>;
            mods = <(MOD_RSFT)>;
            
        };

        K5_key_lshift_link:K5_key_lshift_link { label = "K5_KEY_LSHIFT_LINK"; compatible = "zmk,behavior-mod-morph"; #binding-cells = <0>;
            bindings = <&kp SLASH>, <&K5_key_lshift_sink>;
            mods = <(MOD_LSFT)>;
            
        };

        K5_key_lshift_sink:K5_key_lshift_sink { label = "K5_KEY_LSHIFT_SINK"; compatible = "zmk,behavior-mod-morph"; #binding-cells = <0>;
            bindings = <&kp LA(F18)>, <&kp SLASH>;
            mods = <(MOD_LALT|MOD_LCTL|MOD_LGUI|MOD_RALT|MOD_RCTL|MOD_RGUI|MOD_RSFT)>;
            keep-mods = <(MOD_LALT|MOD_LCTL|MOD_LGUI|MOD_RALT|MOD_RCTL|MOD_RGUI|MOD_RSFT)>;
        };

        K5_key_rshift_sink:K5_key_rshift_sink { label = "K5_KEY_RSHIFT_SINK"; compatible = "zmk,behavior-mod-morph"; #binding-cells = <0>;
            bindings = <&kp RA(F18)>, <&kp SLASH>;
            mods = <(MOD_LALT|MOD_LCTL|MOD_LGUI|MOD_LSFT|MOD_RALT|MOD_RCTL|MOD_RGUI)>;
            keep-mods = <(MOD_LALT|MOD_LCTL|MOD_LGUI|MOD_LSFT|MOD_RALT|MOD_RCTL|MOD_RGUI)>;
        };

        K6_key:K6_key { label = "K6_KEY"; compatible = "zmk,behavior-mod-morph"; #binding-cells = <0>;
            bindings = <&K6_key_lshift_link>, <&K6_key_rshift_sink>;
            mods = <(MOD_RSFT)>;
            
        };

        K6_key_lshift_link:K6_key_lshift_link { label = "K6_KEY_LSHIFT_LINK"; compatible = "zmk,behavior-mod-morph"; #binding-cells = <0>;
            bindings = <&kp TILDE>, <&K6_key_lshift_sink>;
            mods = <(MOD_LSFT)>;
            
        };

        K6_key_lshift_sink:K6_key_lshift_sink { label = "K6_KEY_LSHIFT_SINK"; compatible = "zmk,behavior-mod-morph"; #binding-cells = <0>;
            bindings = <&kp LA(F19)>, <&kp TILDE>;
            mods = <(MOD_LALT|MOD_LCTL|MOD_LGUI|MOD_RALT|MOD_RCTL|MOD_RGUI|MOD_RSFT)>;
            keep-mods = <(MOD_LALT|MOD_LCTL|MOD_LGUI|MOD_RALT|MOD_RCTL|MOD_RGUI|MOD_RSFT)>;
        };

        K6_key_rshift_sink:K6_key_rshift_sink { label = "K6_KEY_RSHIFT_SINK"; compatible = "zmk,behavior-mod-morph"; #binding-cells = <0>;
            bindings = <&kp RA(F19)>, <&kp TILDE>;
            mods = <(MOD_LALT|MOD_LCTL|MOD_LGUI|MOD_LSFT|MOD_RALT|MOD_RCTL|MOD_RGUI)>;
            keep-mods = <(MOD_LALT|MOD_LCTL|MOD_LGUI|MOD_LSFT|MOD_RALT|MOD_RCTL|MOD_RGUI)>;
        };

        C6_key:C6_key { label = "C6_KEY"; compatible = "zmk,behavior-mod-morph"; #binding-cells = <0>;
            bindings = <&kp ESCAPE>, <&C6_key_lshift_sink>;
            mods = <(MOD_LSFT)>;
            
        };

        C6_key_lshift_sink:C6_key_lshift_sink { label = "C6_KEY_LSHIFT_SINK"; compatible = "zmk,behavior-mod-morph"; #binding-cells = <0>;
            bindings = <&kp LC(A)>, <&kp ESCAPE>;
            mods = <(MOD_LALT|MOD_LCTL|MOD_LGUI|MOD_RALT|MOD_RCTL|MOD_RGUI|MOD_RSFT)>;
            keep-mods = <(MOD_LALT|MOD_LCTL|MOD_LGUI|MOD_RALT|MOD_RCTL|MOD_RGUI|MOD_RSFT)>;
        };

        N6_key:N6_key { label = "N6_KEY"; compatible = "zmk,behavior-mod-morph"; #binding-cells = <0>;
            bindings = <&kp ENTER>, <&kp ENTER>;
            mods = <(MOD_LALT|MOD_LCTL|MOD_LGUI|MOD_LSFT|MOD_RALT|MOD_RCTL|MOD_RGUI|MOD_RSFT)>;
            keep-mods = <(MOD_LALT|MOD_LCTL|MOD_LGUI|MOD_LSFT|MOD_RALT|MOD_RCTL|MOD_RGUI|MOD_RSFT)>;
        };

        P6_key:P6_key { label = "P6_KEY"; compatible = "zmk,behavior-mod-morph"; #binding-cells = <0>;
            bindings = <&P6_key_lshift_link>, <&P6_key_rshift_sink>;
            mods = <(MOD_RSFT)>;
            
        };

        P6_key_lshift_link:P6_key_lshift_link { label = "P6_KEY_LSHIFT_LINK"; compatible = "zmk,behavior-mod-morph"; #binding-cells = <0>;
            bindings = <&kp PERIOD>, <&P6_key_lshift_sink>;
            mods = <(MOD_LSFT)>;
            
        };

        P6_key_lshift_sink:P6_key_lshift_sink { label = "P6_KEY_LSHIFT_SINK"; compatible = "zmk,behavior-mod-morph"; #binding-cells = <0>;
            bindings = <&kp LA(F20)>, <&kp PERIOD>;
            mods = <(MOD_LALT|MOD_LCTL|MOD_LGUI|MOD_RALT|MOD_RCTL|MOD_RGUI|MOD_RSFT)>;
            keep-mods = <(MOD_LALT|MOD_LCTL|MOD_LGUI|MOD_RALT|MOD_RCTL|MOD_RGUI|MOD_RSFT)>;
        };

        P6_key_rshift_sink:P6_key_rshift_sink { label = "P6_KEY_RSHIFT_SINK"; compatible = "zmk,behavior-mod-morph"; #binding-cells = <0>;
            bindings = <&kp RA(F20)>, <&kp PERIOD>;
            mods = <(MOD_LALT|MOD_LCTL|MOD_LGUI|MOD_LSFT|MOD_RALT|MOD_RCTL|MOD_RGUI)>;
            keep-mods = <(MOD_LALT|MOD_LCTL|MOD_LGUI|MOD_LSFT|MOD_RALT|MOD_RCTL|MOD_RGUI)>;
        };

        Q1_key:Q1_key { label = "Q1_KEY"; compatible = "zmk,behavior-mod-morph"; #binding-cells = <0>;
            bindings = <&grave_x_gra_gra_gra 0 GRAVE>, <&grave_x_gra_gra_gra 0 GRAVE>;
            mods = <(MOD_LALT|MOD_LCTL|MOD_LGUI|MOD_LSFT|MOD_RALT|MOD_RCTL|MOD_RGUI|MOD_RSFT)>;
            keep-mods = <(MOD_LALT|MOD_LCTL|MOD_LGUI|MOD_LSFT|MOD_RALT|MOD_RCTL|MOD_RGUI|MOD_RSFT)>;
        };

        Q2_key:Q2_key { label = "Q2_KEY"; compatible = "zmk,behavior-mod-morph"; #binding-cells = <0>;
            bindings = <&Q2_key_lshift_link>, <&Q2_key_rshift_sink>;
            mods = <(MOD_RSFT)>;
            
        };

        Q2_key_lshift_link:Q2_key_lshift_link { label = "Q2_KEY_LSHIFT_LINK"; compatible = "zmk,behavior-mod-morph"; #binding-cells = <0>;
            bindings = <&kp AMPERSAND>, <&Q2_key_lshift_sink>;
            mods = <(MOD_LSFT)>;
            
        };

        Q2_key_lshift_sink:Q2_key_lshift_sink { label = "Q2_KEY_LSHIFT_SINK"; compatible = "zmk,behavior-mod-morph"; #binding-cells = <0>;
            bindings = <&kp LA(F21)>, <&kp AMPERSAND>;
            mods = <(MOD_LALT|MOD_LCTL|MOD_LGUI|MOD_RALT|MOD_RCTL|MOD_RGUI|MOD_RSFT)>;
            keep-mods = <(MOD_LALT|MOD_LCTL|MOD_LGUI|MOD_RALT|MOD_RCTL|MOD_RGUI|MOD_RSFT)>;
        };

        Q2_key_rshift_sink:Q2_key_rshift_sink { label = "Q2_KEY_RSHIFT_SINK"; compatible = "zmk,behavior-mod-morph"; #binding-cells = <0>;
            bindings = <&kp RA(F21)>, <&kp AMPERSAND>;
            mods = <(MOD_LALT|MOD_LCTL|MOD_LGUI|MOD_LSFT|MOD_RALT|MOD_RCTL|MOD_RGUI)>;
            keep-mods = <(MOD_LALT|MOD_LCTL|MOD_LGUI|MOD_LSFT|MOD_RALT|MOD_RCTL|MOD_RGUI)>;
        };

        Q4_key:Q4_key { label = "Q4_KEY"; compatible = "zmk,behavior-mod-morph"; #binding-cells = <0>;
            bindings = <&lef_bra_x_rig_bra RIGHT_BRACKET LEFT_BRACKET>, <&lef_bra_x_rig_bra RIGHT_BRACKET LEFT_BRACKET>;
            mods = <(MOD_LALT|MOD_LCTL|MOD_LGUI|MOD_LSFT|MOD_RALT|MOD_RCTL|MOD_RGUI|MOD_RSFT)>;
            keep-mods = <(MOD_LALT|MOD_LCTL|MOD_LGUI|MOD_LSFT|MOD_RALT|MOD_RCTL|MOD_RGUI|MOD_RSFT)>;
        };

        Q5_key:Q5_key { label = "Q5_KEY"; compatible = "zmk,behavior-mod-morph"; #binding-cells = <0>;
            bindings = <&Q5_key_lshift_link>, <&Q5_key_rshift_sink>;
            mods = <(MOD_RSFT)>;
            
        };

        Q5_key_lshift_link:Q5_key_lshift_link { label = "Q5_KEY_LSHIFT_LINK"; compatible = "zmk,behavior-mod-morph"; #binding-cells = <0>;
            bindings = <&lef_par_x_rig_par RIGHT_PARENTHESIS LEFT_PARENTHESIS>, <&Q5_key_lshift_sink>;
            mods = <(MOD_LSFT)>;
            
        };

        Q5_key_lshift_sink:Q5_key_lshift_sink { label = "Q5_KEY_LSHIFT_SINK"; compatible = "zmk,behavior-mod-morph"; #binding-cells = <0>;
            bindings = <&kp RS(KP_NUM)>, <&lef_par_x_rig_par RIGHT_PARENTHESIS LEFT_PARENTHESIS>;
            mods = <(MOD_LALT|MOD_LCTL|MOD_LGUI|MOD_RALT|MOD_RCTL|MOD_RGUI|MOD_RSFT)>;
            keep-mods = <(MOD_LALT|MOD_LCTL|MOD_LGUI|MOD_RALT|MOD_RCTL|MOD_RGUI|MOD_RSFT)>;
        };

        Q5_key_rshift_sink:Q5_key_rshift_sink { label = "Q5_KEY_RSHIFT_SINK"; compatible = "zmk,behavior-mod-morph"; #binding-cells = <0>;
            bindings = <&kp RS(KP_NUM)>, <&lef_par_x_rig_par RIGHT_PARENTHESIS LEFT_PARENTHESIS>;
            mods = <(MOD_LALT|MOD_LCTL|MOD_LGUI|MOD_LSFT|MOD_RALT|MOD_RCTL|MOD_RGUI)>;
            keep-mods = <(MOD_LALT|MOD_LCTL|MOD_LGUI|MOD_LSFT|MOD_RALT|MOD_RCTL|MOD_RGUI)>;
        };

        F6_key:F6_key { label = "F6_KEY"; compatible = "zmk,behavior-mod-morph"; #binding-cells = <0>;
            bindings = <&kp F6>, <&kp F6>;
            mods = <(MOD_LALT|MOD_LCTL|MOD_LGUI|MOD_LSFT|MOD_RALT|MOD_RCTL|MOD_RGUI|MOD_RSFT)>;
            keep-mods = <(MOD_LALT|MOD_LCTL|MOD_LGUI|MOD_LSFT|MOD_RALT|MOD_RCTL|MOD_RGUI|MOD_RSFT)>;
        };

        F7_key:F7_key { label = "F7_KEY"; compatible = "zmk,behavior-mod-morph"; #binding-cells = <0>;
            bindings = <&kp F7>, <&kp F7>;
            mods = <(MOD_LALT|MOD_LCTL|MOD_LGUI|MOD_LSFT|MOD_RALT|MOD_RCTL|MOD_RGUI|MOD_RSFT)>;
            keep-mods = <(MOD_LALT|MOD_LCTL|MOD_LGUI|MOD_LSFT|MOD_RALT|MOD_RCTL|MOD_RGUI|MOD_RSFT)>;
        };

        F8_key:F8_key { label = "F8_KEY"; compatible = "zmk,behavior-mod-morph"; #binding-cells = <0>;
            bindings = <&kp F8>, <&kp F8>;
            mods = <(MOD_LALT|MOD_LCTL|MOD_LGUI|MOD_LSFT|MOD_RALT|MOD_RCTL|MOD_RGUI|MOD_RSFT)>;
            keep-mods = <(MOD_LALT|MOD_LCTL|MOD_LGUI|MOD_LSFT|MOD_RALT|MOD_RCTL|MOD_RGUI|MOD_RSFT)>;
        };

        F9_key:F9_key { label = "F9_KEY"; compatible = "zmk,behavior-mod-morph"; #binding-cells = <0>;
            bindings = <&kp F9>, <&kp F9>;
            mods = <(MOD_LALT|MOD_LCTL|MOD_LGUI|MOD_LSFT|MOD_RALT|MOD_RCTL|MOD_RGUI|MOD_RSFT)>;
            keep-mods = <(MOD_LALT|MOD_LCTL|MOD_LGUI|MOD_LSFT|MOD_RALT|MOD_RCTL|MOD_RGUI|MOD_RSFT)>;
        };

        F0_key:F0_key { label = "F0_KEY"; compatible = "zmk,behavior-mod-morph"; #binding-cells = <0>;
            bindings = <&kp F10>, <&kp F10>;
            mods = <(MOD_LALT|MOD_LCTL|MOD_LGUI|MOD_LSFT|MOD_RALT|MOD_RCTL|MOD_RGUI|MOD_RSFT)>;
            keep-mods = <(MOD_LALT|MOD_LCTL|MOD_LGUI|MOD_LSFT|MOD_RALT|MOD_RCTL|MOD_RGUI|MOD_RSFT)>;
        };

        W9_key:W9_key { label = "W9_KEY"; compatible = "zmk,behavior-mod-morph"; #binding-cells = <0>;
            bindings = <&kp F19>, <&kp F19>;
            mods = <(MOD_LALT|MOD_LCTL|MOD_LGUI|MOD_LSFT|MOD_RALT|MOD_RCTL|MOD_RGUI|MOD_RSFT)>;
            keep-mods = <(MOD_LALT|MOD_LCTL|MOD_LGUI|MOD_LSFT|MOD_RALT|MOD_RCTL|MOD_RGUI|MOD_RSFT)>;
        };

        W0_key:W0_key { label = "W0_KEY"; compatible = "zmk,behavior-mod-morph"; #binding-cells = <0>;
            bindings = <&kp F20>, <&kp F20>;
            mods = <(MOD_LALT|MOD_LCTL|MOD_LGUI|MOD_LSFT|MOD_RALT|MOD_RCTL|MOD_RGUI|MOD_RSFT)>;
            keep-mods = <(MOD_LALT|MOD_LCTL|MOD_LGUI|MOD_LSFT|MOD_RALT|MOD_RCTL|MOD_RGUI|MOD_RSFT)>;
        };

        W_key:W_key { label = "W_KEY"; compatible = "zmk,behavior-mod-morph"; #binding-cells = <0>;
            bindings = <&W_key_lshift_link>, <&W_key_rshift_sink>;
            mods = <(MOD_RSFT)>;
            
        };

        W_key_lshift_link:W_key_lshift_link { label = "W_KEY_LSHIFT_LINK"; compatible = "zmk,behavior-mod-morph"; #binding-cells = <0>;
            bindings = <&kp W>, <&W_key_lshift_sink>;
            mods = <(MOD_LSFT)>;
            
        };

        W_key_lshift_sink:W_key_lshift_sink { label = "W_KEY_LSHIFT_SINK"; compatible = "zmk,behavior-mod-morph"; #binding-cells = <0>;
            bindings = <&kp LS(F5)>, <&kp W>;
            mods = <(MOD_LALT|MOD_LCTL|MOD_LGUI|MOD_RALT|MOD_RCTL|MOD_RGUI|MOD_RSFT)>;
            keep-mods = <(MOD_LALT|MOD_LCTL|MOD_LGUI|MOD_RALT|MOD_RCTL|MOD_RGUI|MOD_RSFT)>;
        };

        W_key_rshift_sink:W_key_rshift_sink { label = "W_KEY_RSHIFT_SINK"; compatible = "zmk,behavior-mod-morph"; #binding-cells = <0>;
            bindings = <&kp RS(F5)>, <&kp W>;
            mods = <(MOD_LALT|MOD_LCTL|MOD_LGUI|MOD_LSFT|MOD_RALT|MOD_RCTL|MOD_RGUI)>;
            keep-mods = <(MOD_LALT|MOD_LCTL|MOD_LGUI|MOD_LSFT|MOD_RALT|MOD_RCTL|MOD_RGUI)>;
        };

        V_key:V_key { label = "V_KEY"; compatible = "zmk,behavior-mod-morph"; #binding-cells = <0>;
            bindings = <&V_key_lctrl_link>, <&V_key_rctrl_sink>;
            mods = <(MOD_RCTL)>;
            
        };

        V_key_lshift_link:V_key_lshift_link { label = "V_KEY_LSHIFT_LINK"; compatible = "zmk,behavior-mod-morph"; #binding-cells = <0>;
            bindings = <&kp V>, <&V_key_lshift_sink>;
            mods = <(MOD_LSFT)>;
            
        };

        V_key_rshift_link:V_key_rshift_link { label = "V_KEY_RSHIFT_LINK"; compatible = "zmk,behavior-mod-morph"; #binding-cells = <0>;
            bindings = <&V_key_lshift_link>, <&V_key_rshift_sink>;
            mods = <(MOD_RSFT)>;
            
        };

        V_key_lctrl_link:V_key_lctrl_link { label = "V_KEY_LCTRL_LINK"; compatible = "zmk,behavior-mod-morph"; #binding-cells = <0>;
            bindings = <&V_key_rshift_link>, <&V_key_lctrl_sink>;
            mods = <(MOD_LCTL)>;
            
        };

        V_key_lshift_sink:V_key_lshift_sink { label = "V_KEY_LSHIFT_SINK"; compatible = "zmk,behavior-mod-morph"; #binding-cells = <0>;
            bindings = <&kp LS(F14)>, <&kp V>;
            mods = <(MOD_LALT|MOD_LCTL|MOD_LGUI|MOD_RALT|MOD_RCTL|MOD_RGUI|MOD_RSFT)>;
            keep-mods = <(MOD_LALT|MOD_LCTL|MOD_LGUI|MOD_RALT|MOD_RCTL|MOD_RGUI|MOD_RSFT)>;
        };

        V_key_rshift_sink:V_key_rshift_sink { label = "V_KEY_RSHIFT_SINK"; compatible = "zmk,behavior-mod-morph"; #binding-cells = <0>;
            bindings = <&kp RS(F14)>, <&kp V>;
            mods = <(MOD_LALT|MOD_LCTL|MOD_LGUI|MOD_LSFT|MOD_RALT|MOD_RCTL|MOD_RGUI)>;
            keep-mods = <(MOD_LALT|MOD_LCTL|MOD_LGUI|MOD_LSFT|MOD_RALT|MOD_RCTL|MOD_RGUI)>;
        };

        V_key_lctrl_sink:V_key_lctrl_sink { label = "V_KEY_LCTRL_SINK"; compatible = "zmk,behavior-mod-morph"; #binding-cells = <0>;
            bindings = <&kp LC(F14)>, <&kp V>;
            mods = <(MOD_LALT|MOD_LGUI|MOD_LSFT|MOD_RALT|MOD_RCTL|MOD_RGUI|MOD_RSFT)>;
            keep-mods = <(MOD_LALT|MOD_LGUI|MOD_LSFT|MOD_RALT|MOD_RCTL|MOD_RGUI|MOD_RSFT)>;
        };

        V_key_rctrl_sink:V_key_rctrl_sink { label = "V_KEY_RCTRL_SINK"; compatible = "zmk,behavior-mod-morph"; #binding-cells = <0>;
            bindings = <&kp RC(F14)>, <&kp V>;
            mods = <(MOD_LALT|MOD_LCTL|MOD_LGUI|MOD_LSFT|MOD_RALT|MOD_RGUI|MOD_RSFT)>;
            keep-mods = <(MOD_LALT|MOD_LCTL|MOD_LGUI|MOD_LSFT|MOD_RALT|MOD_RGUI|MOD_RSFT)>;
        };

        L_key:L_key { label = "L_KEY"; compatible = "zmk,behavior-mod-morph"; #binding-cells = <0>;
            bindings = <&L_key_lshift_link>, <&L_key_rshift_sink>;
            mods = <(MOD_RSFT)>;
            
        };

        L_key_lshift_link:L_key_lshift_link { label = "L_KEY_LSHIFT_LINK"; compatible = "zmk,behavior-mod-morph"; #binding-cells = <0>;
            bindings = <&kp L>, <&L_key_lshift_sink>;
            mods = <(MOD_LSFT)>;
            
        };

        L_key_lshift_sink:L_key_lshift_sink { label = "L_KEY_LSHIFT_SINK"; compatible = "zmk,behavior-mod-morph"; #binding-cells = <0>;
            bindings = <&kp LS(F15)>, <&kp L>;
            mods = <(MOD_LALT|MOD_LCTL|MOD_LGUI|MOD_RALT|MOD_RCTL|MOD_RGUI|MOD_RSFT)>;
            keep-mods = <(MOD_LALT|MOD_LCTL|MOD_LGUI|MOD_RALT|MOD_RCTL|MOD_RGUI|MOD_RSFT)>;
        };

        L_key_rshift_sink:L_key_rshift_sink { label = "L_KEY_RSHIFT_SINK"; compatible = "zmk,behavior-mod-morph"; #binding-cells = <0>;
            bindings = <&kp RS(F15)>, <&kp L>;
            mods = <(MOD_LALT|MOD_LCTL|MOD_LGUI|MOD_LSFT|MOD_RALT|MOD_RCTL|MOD_RGUI)>;
            keep-mods = <(MOD_LALT|MOD_LCTL|MOD_LGUI|MOD_LSFT|MOD_RALT|MOD_RCTL|MOD_RGUI)>;
        };

        B_key:B_key { label = "B_KEY"; compatible = "zmk,behavior-mod-morph"; #binding-cells = <0>;
            bindings = <&B_key_lshift_link>, <&B_key_rshift_sink>;
            mods = <(MOD_RSFT)>;
            
        };

        B_key_lshift_link:B_key_lshift_link { label = "B_KEY_LSHIFT_LINK"; compatible = "zmk,behavior-mod-morph"; #binding-cells = <0>;
            bindings = <&kp B>, <&B_key_lshift_sink>;
            mods = <(MOD_LSFT)>;
            
        };

        B_key_lshift_sink:B_key_lshift_sink { label = "B_KEY_LSHIFT_SINK"; compatible = "zmk,behavior-mod-morph"; #binding-cells = <0>;
            bindings = <&kp LS(F16)>, <&kp B>;
            mods = <(MOD_LALT|MOD_LCTL|MOD_LGUI|MOD_RALT|MOD_RCTL|MOD_RGUI|MOD_RSFT)>;
            keep-mods = <(MOD_LALT|MOD_LCTL|MOD_LGUI|MOD_RALT|MOD_RCTL|MOD_RGUI|MOD_RSFT)>;
        };

        B_key_rshift_sink:B_key_rshift_sink { label = "B_KEY_RSHIFT_SINK"; compatible = "zmk,behavior-mod-morph"; #binding-cells = <0>;
            bindings = <&kp RS(F16)>, <&kp B>;
            mods = <(MOD_LALT|MOD_LCTL|MOD_LGUI|MOD_LSFT|MOD_RALT|MOD_RCTL|MOD_RGUI)>;
            keep-mods = <(MOD_LALT|MOD_LCTL|MOD_LGUI|MOD_LSFT|MOD_RALT|MOD_RCTL|MOD_RGUI)>;
        };

        T_key:T_key { label = "T_KEY"; compatible = "zmk,behavior-mod-morph"; #binding-cells = <0>;
            bindings = <&T_key_lshift_link>, <&T_key_rshift_sink>;
            mods = <(MOD_RSFT)>;
            
        };

        T_key_lshift_link:T_key_lshift_link { label = "T_KEY_LSHIFT_LINK"; compatible = "zmk,behavior-mod-morph"; #binding-cells = <0>;
            bindings = <&T_key_hold_tap RCTRL T>, <&T_key_lshift_sink>;
            mods = <(MOD_LSFT)>;
            
        };

        T_key_lshift_sink:T_key_lshift_sink { label = "T_KEY_LSHIFT_SINK"; compatible = "zmk,behavior-mod-morph"; #binding-cells = <0>;
            bindings = <&kp LS(F17)>, <&T_key_hold_tap RCTRL T>;
            mods = <(MOD_LALT|MOD_LCTL|MOD_LGUI|MOD_RALT|MOD_RCTL|MOD_RGUI|MOD_RSFT)>;
            keep-mods = <(MOD_LALT|MOD_LCTL|MOD_LGUI|MOD_RALT|MOD_RCTL|MOD_RGUI|MOD_RSFT)>;
        };

        T_key_rshift_sink:T_key_rshift_sink { label = "T_KEY_RSHIFT_SINK"; compatible = "zmk,behavior-mod-morph"; #binding-cells = <0>;
            bindings = <&kp RS(F17)>, <&T_key_hold_tap RCTRL T>;
            mods = <(MOD_LALT|MOD_LCTL|MOD_LGUI|MOD_LSFT|MOD_RALT|MOD_RCTL|MOD_RGUI)>;
            keep-mods = <(MOD_LALT|MOD_LCTL|MOD_LGUI|MOD_LSFT|MOD_RALT|MOD_RCTL|MOD_RGUI)>;
        };

        R_key:R_key { label = "R_KEY"; compatible = "zmk,behavior-mod-morph"; #binding-cells = <0>;
            bindings = <&R_key_lshift_link>, <&R_key_rshift_sink>;
            mods = <(MOD_RSFT)>;
            
        };

        R_key_lshift_link:R_key_lshift_link { label = "R_KEY_LSHIFT_LINK"; compatible = "zmk,behavior-mod-morph"; #binding-cells = <0>;
            bindings = <&R_key_hold_tap RSHIFT R>, <&R_key_lshift_sink>;
            mods = <(MOD_LSFT)>;
            
        };

        R_key_lshift_sink:R_key_lshift_sink { label = "R_KEY_LSHIFT_SINK"; compatible = "zmk,behavior-mod-morph"; #binding-cells = <0>;
            bindings = <&kp LS(F18)>, <&R_key_hold_tap RSHIFT R>;
            mods = <(MOD_LALT|MOD_LCTL|MOD_LGUI|MOD_RALT|MOD_RCTL|MOD_RGUI|MOD_RSFT)>;
            keep-mods = <(MOD_LALT|MOD_LCTL|MOD_LGUI|MOD_RALT|MOD_RCTL|MOD_RGUI|MOD_RSFT)>;
        };

        R_key_rshift_sink:R_key_rshift_sink { label = "R_KEY_RSHIFT_SINK"; compatible = "zmk,behavior-mod-morph"; #binding-cells = <0>;
            bindings = <&kp RS(F18)>, <&R_key_hold_tap RSHIFT R>;
            mods = <(MOD_LALT|MOD_LCTL|MOD_LGUI|MOD_LSFT|MOD_RALT|MOD_RCTL|MOD_RGUI)>;
            keep-mods = <(MOD_LALT|MOD_LCTL|MOD_LGUI|MOD_LSFT|MOD_RALT|MOD_RCTL|MOD_RGUI)>;
        };

        E_key:E_key { label = "E_KEY"; compatible = "zmk,behavior-mod-morph"; #binding-cells = <0>;
            bindings = <&E_key_lshift_link>, <&E_key_rshift_sink>;
            mods = <(MOD_RSFT)>;
            
        };

        E_key_lshift_link:E_key_lshift_link { label = "E_KEY_LSHIFT_LINK"; compatible = "zmk,behavior-mod-morph"; #binding-cells = <0>;
            bindings = <&E_key_hold_tap RALT E>, <&E_key_lshift_sink>;
            mods = <(MOD_LSFT)>;
            
        };

        E_key_lshift_sink:E_key_lshift_sink { label = "E_KEY_LSHIFT_SINK"; compatible = "zmk,behavior-mod-morph"; #binding-cells = <0>;
            bindings = <&kp LS(F19)>, <&E_key_hold_tap RALT E>;
            mods = <(MOD_LALT|MOD_LCTL|MOD_LGUI|MOD_RALT|MOD_RCTL|MOD_RGUI|MOD_RSFT)>;
            keep-mods = <(MOD_LALT|MOD_LCTL|MOD_LGUI|MOD_RALT|MOD_RCTL|MOD_RGUI|MOD_RSFT)>;
        };

        E_key_rshift_sink:E_key_rshift_sink { label = "E_KEY_RSHIFT_SINK"; compatible = "zmk,behavior-mod-morph"; #binding-cells = <0>;
            bindings = <&kp RS(F19)>, <&E_key_hold_tap RALT E>;
            mods = <(MOD_LALT|MOD_LCTL|MOD_LGUI|MOD_LSFT|MOD_RALT|MOD_RCTL|MOD_RGUI)>;
            keep-mods = <(MOD_LALT|MOD_LCTL|MOD_LGUI|MOD_LSFT|MOD_RALT|MOD_RCTL|MOD_RGUI)>;
        };

        S_key:S_key { label = "S_KEY"; compatible = "zmk,behavior-mod-morph"; #binding-cells = <0>;
            bindings = <&S_key_lctrl_link>, <&S_key_rctrl_sink>;
            mods = <(MOD_RCTL)>;
            
        };

        S_key_lshift_link:S_key_lshift_link { label = "S_KEY_LSHIFT_LINK"; compatible = "zmk,behavior-mod-morph"; #binding-cells = <0>;
            bindings = <&kp S>, <&S_key_lshift_sink>;
            mods = <(MOD_LSFT)>;
            
        };

        S_key_rshift_link:S_key_rshift_link { label = "S_KEY_RSHIFT_LINK"; compatible = "zmk,behavior-mod-morph"; #binding-cells = <0>;
            bindings = <&S_key_lshift_link>, <&S_key_rshift_sink>;
            mods = <(MOD_RSFT)>;
            
        };

        S_key_lctrl_link:S_key_lctrl_link { label = "S_KEY_LCTRL_LINK"; compatible = "zmk,behavior-mod-morph"; #binding-cells = <0>;
            bindings = <&S_key_rshift_link>, <&S_key_lctrl_sink>;
            mods = <(MOD_LCTL)>;
            
        };

        S_key_lshift_sink:S_key_lshift_sink { label = "S_KEY_LSHIFT_SINK"; compatible = "zmk,behavior-mod-morph"; #binding-cells = <0>;
            bindings = <&kp LS(F20)>, <&kp S>;
            mods = <(MOD_LALT|MOD_LCTL|MOD_LGUI|MOD_RALT|MOD_RCTL|MOD_RGUI|MOD_RSFT)>;
            keep-mods = <(MOD_LALT|MOD_LCTL|MOD_LGUI|MOD_RALT|MOD_RCTL|MOD_RGUI|MOD_RSFT)>;
        };

        S_key_rshift_sink:S_key_rshift_sink { label = "S_KEY_RSHIFT_SINK"; compatible = "zmk,behavior-mod-morph"; #binding-cells = <0>;
            bindings = <&kp RS(F20)>, <&kp S>;
            mods = <(MOD_LALT|MOD_LCTL|MOD_LGUI|MOD_LSFT|MOD_RALT|MOD_RCTL|MOD_RGUI)>;
            keep-mods = <(MOD_LALT|MOD_LCTL|MOD_LGUI|MOD_LSFT|MOD_RALT|MOD_RCTL|MOD_RGUI)>;
        };

        S_key_lctrl_sink:S_key_lctrl_sink { label = "S_KEY_LCTRL_SINK"; compatible = "zmk,behavior-mod-morph"; #binding-cells = <0>;
            bindings = <&kp LC(F20)>, <&kp S>;
            mods = <(MOD_LALT|MOD_LGUI|MOD_LSFT|MOD_RALT|MOD_RCTL|MOD_RGUI|MOD_RSFT)>;
            keep-mods = <(MOD_LALT|MOD_LGUI|MOD_LSFT|MOD_RALT|MOD_RCTL|MOD_RGUI|MOD_RSFT)>;
        };

        S_key_rctrl_sink:S_key_rctrl_sink { label = "S_KEY_RCTRL_SINK"; compatible = "zmk,behavior-mod-morph"; #binding-cells = <0>;
            bindings = <&kp RC(F20)>, <&kp S>;
            mods = <(MOD_LALT|MOD_LCTL|MOD_LGUI|MOD_LSFT|MOD_RALT|MOD_RGUI|MOD_RSFT)>;
            keep-mods = <(MOD_LALT|MOD_LCTL|MOD_LGUI|MOD_LSFT|MOD_RALT|MOD_RGUI|MOD_RSFT)>;
        };

        M_key:M_key { label = "M_KEY"; compatible = "zmk,behavior-mod-morph"; #binding-cells = <0>;
            bindings = <&M_key_lshift_link>, <&M_key_rshift_sink>;
            mods = <(MOD_RSFT)>;
            
        };

        M_key_lshift_link:M_key_lshift_link { label = "M_KEY_LSHIFT_LINK"; compatible = "zmk,behavior-mod-morph"; #binding-cells = <0>;
            bindings = <&kp M>, <&M_key_lshift_sink>;
            mods = <(MOD_LSFT)>;
            
        };

        M_key_lshift_sink:M_key_lshift_sink { label = "M_KEY_LSHIFT_SINK"; compatible = "zmk,behavior-mod-morph"; #binding-cells = <0>;
            bindings = <&kp LS(F21)>, <&kp M>;
            mods = <(MOD_LALT|MOD_LCTL|MOD_LGUI|MOD_RALT|MOD_RCTL|MOD_RGUI|MOD_RSFT)>;
            keep-mods = <(MOD_LALT|MOD_LCTL|MOD_LGUI|MOD_RALT|MOD_RCTL|MOD_RGUI|MOD_RSFT)>;
        };

        M_key_rshift_sink:M_key_rshift_sink { label = "M_KEY_RSHIFT_SINK"; compatible = "zmk,behavior-mod-morph"; #binding-cells = <0>;
            bindings = <&kp RS(F21)>, <&kp M>;
            mods = <(MOD_LALT|MOD_LCTL|MOD_LGUI|MOD_LSFT|MOD_RALT|MOD_RCTL|MOD_RGUI)>;
            keep-mods = <(MOD_LALT|MOD_LCTL|MOD_LGUI|MOD_LSFT|MOD_RALT|MOD_RCTL|MOD_RGUI)>;
        };

        D_key:D_key { label = "D_KEY"; compatible = "zmk,behavior-mod-morph"; #binding-cells = <0>;
            bindings = <&D_key_lshift_link>, <&D_key_rshift_sink>;
            mods = <(MOD_RSFT)>;
            
        };

        D_key_lshift_link:D_key_lshift_link { label = "D_KEY_LSHIFT_LINK"; compatible = "zmk,behavior-mod-morph"; #binding-cells = <0>;
            bindings = <&kp D>, <&D_key_lshift_sink>;
            mods = <(MOD_LSFT)>;
            
        };

        D_key_lshift_sink:D_key_lshift_sink { label = "D_KEY_LSHIFT_SINK"; compatible = "zmk,behavior-mod-morph"; #binding-cells = <0>;
            bindings = <&kp LS(F22)>, <&kp D>;
            mods = <(MOD_LALT|MOD_LCTL|MOD_LGUI|MOD_RALT|MOD_RCTL|MOD_RGUI|MOD_RSFT)>;
            keep-mods = <(MOD_LALT|MOD_LCTL|MOD_LGUI|MOD_RALT|MOD_RCTL|MOD_RGUI|MOD_RSFT)>;
        };

        D_key_rshift_sink:D_key_rshift_sink { label = "D_KEY_RSHIFT_SINK"; compatible = "zmk,behavior-mod-morph"; #binding-cells = <0>;
            bindings = <&kp RS(F22)>, <&kp D>;
            mods = <(MOD_LALT|MOD_LCTL|MOD_LGUI|MOD_LSFT|MOD_RALT|MOD_RCTL|MOD_RGUI)>;
            keep-mods = <(MOD_LALT|MOD_LCTL|MOD_LGUI|MOD_LSFT|MOD_RALT|MOD_RCTL|MOD_RGUI)>;
        };

        Y_key:Y_key { label = "Y_KEY"; compatible = "zmk,behavior-mod-morph"; #binding-cells = <0>;
            bindings = <&Y_key_lctrl_link>, <&Y_key_rctrl_sink>;
            mods = <(MOD_RCTL)>;
            
        };

        Y_key_lshift_link:Y_key_lshift_link { label = "Y_KEY_LSHIFT_LINK"; compatible = "zmk,behavior-mod-morph"; #binding-cells = <0>;
            bindings = <&kp Y>, <&Y_key_lshift_sink>;
            mods = <(MOD_LSFT)>;
            
        };

        Y_key_rshift_link:Y_key_rshift_link { label = "Y_KEY_RSHIFT_LINK"; compatible = "zmk,behavior-mod-morph"; #binding-cells = <0>;
            bindings = <&Y_key_lshift_link>, <&Y_key_rshift_sink>;
            mods = <(MOD_RSFT)>;
            
        };

        Y_key_lctrl_link:Y_key_lctrl_link { label = "Y_KEY_LCTRL_LINK"; compatible = "zmk,behavior-mod-morph"; #binding-cells = <0>;
            bindings = <&Y_key_rshift_link>, <&Y_key_lctrl_sink>;
            mods = <(MOD_LCTL)>;
            
        };

        Y_key_lshift_sink:Y_key_lshift_sink { label = "Y_KEY_LSHIFT_SINK"; compatible = "zmk,behavior-mod-morph"; #binding-cells = <0>;
            bindings = <&kp LS(F23)>, <&kp Y>;
            mods = <(MOD_LALT|MOD_LCTL|MOD_LGUI|MOD_RALT|MOD_RCTL|MOD_RGUI|MOD_RSFT)>;
            keep-mods = <(MOD_LALT|MOD_LCTL|MOD_LGUI|MOD_RALT|MOD_RCTL|MOD_RGUI|MOD_RSFT)>;
        };

        Y_key_rshift_sink:Y_key_rshift_sink { label = "Y_KEY_RSHIFT_SINK"; compatible = "zmk,behavior-mod-morph"; #binding-cells = <0>;
            bindings = <&kp RS(F23)>, <&kp Y>;
            mods = <(MOD_LALT|MOD_LCTL|MOD_LGUI|MOD_LSFT|MOD_RALT|MOD_RCTL|MOD_RGUI)>;
            keep-mods = <(MOD_LALT|MOD_LCTL|MOD_LGUI|MOD_LSFT|MOD_RALT|MOD_RCTL|MOD_RGUI)>;
        };

        Y_key_lctrl_sink:Y_key_lctrl_sink { label = "Y_KEY_LCTRL_SINK"; compatible = "zmk,behavior-mod-morph"; #binding-cells = <0>;
            bindings = <&kp LC(F23)>, <&kp Y>;
            mods = <(MOD_LALT|MOD_LGUI|MOD_LSFT|MOD_RALT|MOD_RCTL|MOD_RGUI|MOD_RSFT)>;
            keep-mods = <(MOD_LALT|MOD_LGUI|MOD_LSFT|MOD_RALT|MOD_RCTL|MOD_RGUI|MOD_RSFT)>;
        };

        Y_key_rctrl_sink:Y_key_rctrl_sink { label = "Y_KEY_RCTRL_SINK"; compatible = "zmk,behavior-mod-morph"; #binding-cells = <0>;
            bindings = <&kp RC(F23)>, <&kp Y>;
            mods = <(MOD_LALT|MOD_LCTL|MOD_LGUI|MOD_LSFT|MOD_RALT|MOD_RGUI|MOD_RSFT)>;
            keep-mods = <(MOD_LALT|MOD_LCTL|MOD_LGUI|MOD_LSFT|MOD_RALT|MOD_RGUI|MOD_RSFT)>;
        };

        X_key:X_key { label = "X_KEY"; compatible = "zmk,behavior-mod-morph"; #binding-cells = <0>;
            bindings = <&X_key_lctrl_link>, <&X_key_rctrl_sink>;
            mods = <(MOD_RCTL)>;
            
        };

        X_key_lshift_link:X_key_lshift_link { label = "X_KEY_LSHIFT_LINK"; compatible = "zmk,behavior-mod-morph"; #binding-cells = <0>;
            bindings = <&kp X>, <&X_key_lshift_sink>;
            mods = <(MOD_LSFT)>;
            
        };

        X_key_rshift_link:X_key_rshift_link { label = "X_KEY_RSHIFT_LINK"; compatible = "zmk,behavior-mod-morph"; #binding-cells = <0>;
            bindings = <&X_key_lshift_link>, <&X_key_rshift_sink>;
            mods = <(MOD_RSFT)>;
            
        };

        X_key_lctrl_link:X_key_lctrl_link { label = "X_KEY_LCTRL_LINK"; compatible = "zmk,behavior-mod-morph"; #binding-cells = <0>;
            bindings = <&X_key_rshift_link>, <&X_key_lctrl_sink>;
            mods = <(MOD_LCTL)>;
            
        };

        X_key_lshift_sink:X_key_lshift_sink { label = "X_KEY_LSHIFT_SINK"; compatible = "zmk,behavior-mod-morph"; #binding-cells = <0>;
            bindings = <&kp LS(F24)>, <&kp X>;
            mods = <(MOD_LALT|MOD_LCTL|MOD_LGUI|MOD_RALT|MOD_RCTL|MOD_RGUI|MOD_RSFT)>;
            keep-mods = <(MOD_LALT|MOD_LCTL|MOD_LGUI|MOD_RALT|MOD_RCTL|MOD_RGUI|MOD_RSFT)>;
        };

        X_key_rshift_sink:X_key_rshift_sink { label = "X_KEY_RSHIFT_SINK"; compatible = "zmk,behavior-mod-morph"; #binding-cells = <0>;
            bindings = <&kp RS(F24)>, <&kp X>;
            mods = <(MOD_LALT|MOD_LCTL|MOD_LGUI|MOD_LSFT|MOD_RALT|MOD_RCTL|MOD_RGUI)>;
            keep-mods = <(MOD_LALT|MOD_LCTL|MOD_LGUI|MOD_LSFT|MOD_RALT|MOD_RCTL|MOD_RGUI)>;
        };

        X_key_lctrl_sink:X_key_lctrl_sink { label = "X_KEY_LCTRL_SINK"; compatible = "zmk,behavior-mod-morph"; #binding-cells = <0>;
            bindings = <&kp LC(F24)>, <&kp X>;
            mods = <(MOD_LALT|MOD_LGUI|MOD_LSFT|MOD_RALT|MOD_RCTL|MOD_RGUI|MOD_RSFT)>;
            keep-mods = <(MOD_LALT|MOD_LGUI|MOD_LSFT|MOD_RALT|MOD_RCTL|MOD_RGUI|MOD_RSFT)>;
        };

        X_key_rctrl_sink:X_key_rctrl_sink { label = "X_KEY_RCTRL_SINK"; compatible = "zmk,behavior-mod-morph"; #binding-cells = <0>;
            bindings = <&kp RC(F24)>, <&kp X>;
            mods = <(MOD_LALT|MOD_LCTL|MOD_LGUI|MOD_LSFT|MOD_RALT|MOD_RGUI|MOD_RSFT)>;
            keep-mods = <(MOD_LALT|MOD_LCTL|MOD_LGUI|MOD_LSFT|MOD_RALT|MOD_RGUI|MOD_RSFT)>;
        };

        Z_key:Z_key { label = "Z_KEY"; compatible = "zmk,behavior-mod-morph"; #binding-cells = <0>;
            bindings = <&Z_key_lctrl_link>, <&Z_key_rctrl_sink>;
            mods = <(MOD_RCTL)>;
            
        };

        Z_key_lshift_link:Z_key_lshift_link { label = "Z_KEY_LSHIFT_LINK"; compatible = "zmk,behavior-mod-morph"; #binding-cells = <0>;
            bindings = <&kp Z>, <&Z_key_lshift_sink>;
            mods = <(MOD_LSFT)>;
            
        };

        Z_key_rshift_link:Z_key_rshift_link { label = "Z_KEY_RSHIFT_LINK"; compatible = "zmk,behavior-mod-morph"; #binding-cells = <0>;
            bindings = <&Z_key_lshift_link>, <&Z_key_rshift_sink>;
            mods = <(MOD_RSFT)>;
            
        };

        Z_key_lctrl_link:Z_key_lctrl_link { label = "Z_KEY_LCTRL_LINK"; compatible = "zmk,behavior-mod-morph"; #binding-cells = <0>;
            bindings = <&Z_key_rshift_link>, <&Z_key_lctrl_sink>;
            mods = <(MOD_LCTL)>;
            
        };

        Z_key_lshift_sink:Z_key_lshift_sink { label = "Z_KEY_LSHIFT_SINK"; compatible = "zmk,behavior-mod-morph"; #binding-cells = <0>;
            bindings = <&kp LS(INS)>, <&kp Z>;
            mods = <(MOD_LALT|MOD_LCTL|MOD_LGUI|MOD_RALT|MOD_RCTL|MOD_RGUI|MOD_RSFT)>;
            keep-mods = <(MOD_LALT|MOD_LCTL|MOD_LGUI|MOD_RALT|MOD_RCTL|MOD_RGUI|MOD_RSFT)>;
        };

        Z_key_rshift_sink:Z_key_rshift_sink { label = "Z_KEY_RSHIFT_SINK"; compatible = "zmk,behavior-mod-morph"; #binding-cells = <0>;
            bindings = <&kp RS(INS)>, <&kp Z>;
            mods = <(MOD_LALT|MOD_LCTL|MOD_LGUI|MOD_LSFT|MOD_RALT|MOD_RCTL|MOD_RGUI)>;
            keep-mods = <(MOD_LALT|MOD_LCTL|MOD_LGUI|MOD_LSFT|MOD_RALT|MOD_RCTL|MOD_RGUI)>;
        };

        Z_key_lctrl_sink:Z_key_lctrl_sink { label = "Z_KEY_LCTRL_SINK"; compatible = "zmk,behavior-mod-morph"; #binding-cells = <0>;
            bindings = <&kp LC(INS)>, <&kp Z>;
            mods = <(MOD_LALT|MOD_LGUI|MOD_LSFT|MOD_RALT|MOD_RCTL|MOD_RGUI|MOD_RSFT)>;
            keep-mods = <(MOD_LALT|MOD_LGUI|MOD_LSFT|MOD_RALT|MOD_RCTL|MOD_RGUI|MOD_RSFT)>;
        };

        Z_key_rctrl_sink:Z_key_rctrl_sink { label = "Z_KEY_RCTRL_SINK"; compatible = "zmk,behavior-mod-morph"; #binding-cells = <0>;
            bindings = <&kp RC(INS)>, <&kp Z>;
            mods = <(MOD_LALT|MOD_LCTL|MOD_LGUI|MOD_LSFT|MOD_RALT|MOD_RGUI|MOD_RSFT)>;
            keep-mods = <(MOD_LALT|MOD_LCTL|MOD_LGUI|MOD_LSFT|MOD_RALT|MOD_RGUI|MOD_RSFT)>;
        };

        W5_key:W5_key { label = "W5_KEY"; compatible = "zmk,behavior-mod-morph"; #binding-cells = <0>;
            bindings = <&kp PERCENT>, <&kp PERCENT>;
            mods = <(MOD_LALT|MOD_LCTL|MOD_LGUI|MOD_LSFT|MOD_RALT|MOD_RCTL|MOD_RGUI|MOD_RSFT)>;
            keep-mods = <(MOD_LALT|MOD_LCTL|MOD_LGUI|MOD_LSFT|MOD_RALT|MOD_RCTL|MOD_RGUI|MOD_RSFT)>;
        };

        V5_key:V5_key { label = "V5_KEY"; compatible = "zmk,behavior-mod-morph"; #binding-cells = <0>;
            bindings = <&kp EQUAL>, <&kp EQUAL>;
            mods = <(MOD_LALT|MOD_LCTL|MOD_LGUI|MOD_LSFT|MOD_RALT|MOD_RCTL|MOD_RGUI|MOD_RSFT)>;
            keep-mods = <(MOD_LALT|MOD_LCTL|MOD_LGUI|MOD_LSFT|MOD_RALT|MOD_RCTL|MOD_RGUI|MOD_RSFT)>;
        };

        T5_key:T5_key { label = "T5_KEY"; compatible = "zmk,behavior-mod-morph"; #binding-cells = <0>;
            bindings = <&kp TAB>, <&kp TAB>;
            mods = <(MOD_LALT|MOD_LCTL|MOD_LGUI|MOD_LSFT|MOD_RALT|MOD_RCTL|MOD_RGUI|MOD_RSFT)>;
            keep-mods = <(MOD_LALT|MOD_LCTL|MOD_LGUI|MOD_LSFT|MOD_RALT|MOD_RCTL|MOD_RGUI|MOD_RSFT)>;
        };

        M5_key:M5_key { label = "M5_KEY"; compatible = "zmk,behavior-mod-morph"; #binding-cells = <0>;
            bindings = <&kp COMMA>, <&kp COMMA>;
            mods = <(MOD_LALT|MOD_LCTL|MOD_LGUI|MOD_LSFT|MOD_RALT|MOD_RCTL|MOD_RGUI|MOD_RSFT)>;
            keep-mods = <(MOD_LALT|MOD_LCTL|MOD_LGUI|MOD_LSFT|MOD_RALT|MOD_RCTL|MOD_RGUI|MOD_RSFT)>;
        };

        W6_key:W6_key { label = "W6_KEY"; compatible = "zmk,behavior-mod-morph"; #binding-cells = <0>;
            bindings = <&kp MINUS>, <&kp MINUS>;
            mods = <(MOD_LALT|MOD_LCTL|MOD_LGUI|MOD_LSFT|MOD_RALT|MOD_RCTL|MOD_RGUI|MOD_RSFT)>;
            keep-mods = <(MOD_LALT|MOD_LCTL|MOD_LGUI|MOD_LSFT|MOD_RALT|MOD_RCTL|MOD_RGUI|MOD_RSFT)>;
        };

        W8_key:W8_key { label = "W8_KEY"; compatible = "zmk,behavior-mod-morph"; #binding-cells = <0>;
            bindings = <&kp PLUS>, <&kp PLUS>;
            mods = <(MOD_LALT|MOD_LCTL|MOD_LGUI|MOD_LSFT|MOD_RALT|MOD_RCTL|MOD_RGUI|MOD_RSFT)>;
            keep-mods = <(MOD_LALT|MOD_LCTL|MOD_LGUI|MOD_LSFT|MOD_RALT|MOD_RCTL|MOD_RGUI|MOD_RSFT)>;
        };

        B9_key:B9_key { label = "B9_KEY"; compatible = "zmk,behavior-mod-morph"; #binding-cells = <0>;
            bindings = <&kp LESS_THAN>, <&kp LESS_THAN>;
            mods = <(MOD_LALT|MOD_LCTL|MOD_LGUI|MOD_LSFT|MOD_RALT|MOD_RCTL|MOD_RGUI|MOD_RSFT)>;
            keep-mods = <(MOD_LALT|MOD_LCTL|MOD_LGUI|MOD_LSFT|MOD_RALT|MOD_RCTL|MOD_RGUI|MOD_RSFT)>;
        };

        B0_key:B0_key { label = "B0_KEY"; compatible = "zmk,behavior-mod-morph"; #binding-cells = <0>;
            bindings = <&kp GREATER_THAN>, <&kp GREATER_THAN>;
            mods = <(MOD_LALT|MOD_LCTL|MOD_LGUI|MOD_LSFT|MOD_RALT|MOD_RCTL|MOD_RGUI|MOD_RSFT)>;
            keep-mods = <(MOD_LALT|MOD_LCTL|MOD_LGUI|MOD_LSFT|MOD_RALT|MOD_RCTL|MOD_RGUI|MOD_RSFT)>;
        };

        S0_key:S0_key { label = "S0_KEY"; compatible = "zmk,behavior-mod-morph"; #binding-cells = <0>;
            bindings = <&kp QUESTION>, <&kp QUESTION>;
            mods = <(MOD_LALT|MOD_LCTL|MOD_LGUI|MOD_LSFT|MOD_RALT|MOD_RCTL|MOD_RGUI|MOD_RSFT)>;
            keep-mods = <(MOD_LALT|MOD_LCTL|MOD_LGUI|MOD_LSFT|MOD_RALT|MOD_RCTL|MOD_RGUI|MOD_RSFT)>;
        };

        X0_key:X0_key { label = "X0_KEY"; compatible = "zmk,behavior-mod-morph"; #binding-cells = <0>;
            bindings = <&kp UNDERSCORE>, <&kp UNDERSCORE>;
            mods = <(MOD_LALT|MOD_LCTL|MOD_LGUI|MOD_LSFT|MOD_RALT|MOD_RCTL|MOD_RGUI|MOD_RSFT)>;
            keep-mods = <(MOD_LALT|MOD_LCTL|MOD_LGUI|MOD_LSFT|MOD_RALT|MOD_RCTL|MOD_RGUI|MOD_RSFT)>;
        };

        Z6_key:Z6_key { label = "Z6_KEY"; compatible = "zmk,behavior-mod-morph"; #binding-cells = <0>;
            bindings = <&Z6_key_lshift_link>, <&Z6_key_rshift_sink>;
            mods = <(MOD_RSFT)>;
            
        };

        Z6_key_lshift_link:Z6_key_lshift_link { label = "Z6_KEY_LSHIFT_LINK"; compatible = "zmk,behavior-mod-morph"; #binding-cells = <0>;
            bindings = <&left_brace_x_rig_bra RIGHT_BRACE LEFT_BRACE>, <&Z6_key_lshift_sink>;
            mods = <(MOD_LSFT)>;
            
        };

        Z6_key_lshift_sink:Z6_key_lshift_sink { label = "Z6_KEY_LSHIFT_SINK"; compatible = "zmk,behavior-mod-morph"; #binding-cells = <0>;
            bindings = <&kp RS(SLCK)>, <&left_brace_x_rig_bra RIGHT_BRACE LEFT_BRACE>;
            mods = <(MOD_LALT|MOD_LCTL|MOD_LGUI|MOD_RALT|MOD_RCTL|MOD_RGUI|MOD_RSFT)>;
            keep-mods = <(MOD_LALT|MOD_LCTL|MOD_LGUI|MOD_RALT|MOD_RCTL|MOD_RGUI|MOD_RSFT)>;
        };

        Z6_key_rshift_sink:Z6_key_rshift_sink { label = "Z6_KEY_RSHIFT_SINK"; compatible = "zmk,behavior-mod-morph"; #binding-cells = <0>;
            bindings = <&kp RS(SLCK)>, <&left_brace_x_rig_bra RIGHT_BRACE LEFT_BRACE>;
            mods = <(MOD_LALT|MOD_LCTL|MOD_LGUI|MOD_LSFT|MOD_RALT|MOD_RCTL|MOD_RGUI)>;
            keep-mods = <(MOD_LALT|MOD_LCTL|MOD_LGUI|MOD_LSFT|MOD_RALT|MOD_RCTL|MOD_RGUI)>;
        };

        Z7_key:Z7_key { label = "Z7_KEY"; compatible = "zmk,behavior-mod-morph"; #binding-cells = <0>;
            bindings = <&kp EXCLAMATION>, <&kp EXCLAMATION>;
            mods = <(MOD_LALT|MOD_LCTL|MOD_LGUI|MOD_LSFT|MOD_RALT|MOD_RCTL|MOD_RGUI|MOD_RSFT)>;
            keep-mods = <(MOD_LALT|MOD_LCTL|MOD_LGUI|MOD_LSFT|MOD_RALT|MOD_RCTL|MOD_RGUI|MOD_RSFT)>;
        };

        Z9_key:Z9_key { label = "Z9_KEY"; compatible = "zmk,behavior-mod-morph"; #binding-cells = <0>;
            bindings = <&kp PIPE>, <&kp PIPE>;
            mods = <(MOD_LALT|MOD_LCTL|MOD_LGUI|MOD_LSFT|MOD_RALT|MOD_RCTL|MOD_RGUI|MOD_RSFT)>;
            keep-mods = <(MOD_LALT|MOD_LCTL|MOD_LGUI|MOD_LSFT|MOD_RALT|MOD_RCTL|MOD_RGUI|MOD_RSFT)>;
        };

        Z0_key:Z0_key { label = "Z0_KEY"; compatible = "zmk,behavior-mod-morph"; #binding-cells = <0>;
            bindings = <&kp AT_SIGN>, <&kp AT_SIGN>;
            mods = <(MOD_LALT|MOD_LCTL|MOD_LGUI|MOD_LSFT|MOD_RALT|MOD_RCTL|MOD_RGUI|MOD_RSFT)>;
            keep-mods = <(MOD_LALT|MOD_LCTL|MOD_LGUI|MOD_LSFT|MOD_RALT|MOD_RCTL|MOD_RGUI|MOD_RSFT)>;
        };

        TL1:TL1 { label = "TL1"; compatible = "zmk,behavior-mod-morph"; #binding-cells = <0>;
            bindings = <&kp SPACE>, <&kp SPACE>;
            mods = <(MOD_LALT|MOD_LCTL|MOD_LGUI|MOD_LSFT|MOD_RALT|MOD_RCTL|MOD_RGUI|MOD_RSFT)>;
            keep-mods = <(MOD_LALT|MOD_LCTL|MOD_LGUI|MOD_LSFT|MOD_RALT|MOD_RCTL|MOD_RGUI|MOD_RSFT)>;
        };

        TL2:TL2 { label = "TL2"; compatible = "zmk,behavior-mod-morph"; #binding-cells = <0>;
            bindings = <&kp BACKSPACE>, <&TL2_lshift_sink>;
            mods = <(MOD_LSFT)>;
            
        };

        TL2_lshift_sink:TL2_lshift_sink { label = "TL2_LSHIFT_SINK"; compatible = "zmk,behavior-mod-morph"; #binding-cells = <0>;
            bindings = <&kp DELETE>, <&kp BACKSPACE>;
            mods = <(MOD_LALT|MOD_LCTL|MOD_LGUI|MOD_RALT|MOD_RCTL|MOD_RGUI|MOD_RSFT)>;
            keep-mods = <(MOD_LALT|MOD_LCTL|MOD_LGUI|MOD_RALT|MOD_RCTL|MOD_RGUI|MOD_RSFT)>;
        };

        TL3:TL3 { label = "TL3"; compatible = "zmk,behavior-mod-morph"; #binding-cells = <0>;
            bindings = <&kp LS(LA(LG(H)))>, <&kp LS(LA(LG(H)))>;
            mods = <(MOD_LALT|MOD_LCTL|MOD_LGUI|MOD_LSFT|MOD_RALT|MOD_RCTL|MOD_RGUI|MOD_RSFT)>;
            keep-mods = <(MOD_LALT|MOD_LCTL|MOD_LGUI|MOD_LSFT|MOD_RALT|MOD_RCTL|MOD_RGUI|MOD_RSFT)>;
        };

        TL4:TL4 { label = "TL4"; compatible = "zmk,behavior-mod-morph"; #binding-cells = <0>;
            bindings = <&sl 4>, <&sl 4>;
            mods = <(MOD_LALT|MOD_LCTL|MOD_LGUI|MOD_LSFT|MOD_RALT|MOD_RCTL|MOD_RGUI|MOD_RSFT)>;
            keep-mods = <(MOD_LALT|MOD_LCTL|MOD_LGUI|MOD_LSFT|MOD_RALT|MOD_RCTL|MOD_RGUI|MOD_RSFT)>;
        };

        TL5:TL5 { label = "TL5"; compatible = "zmk,behavior-mod-morph"; #binding-cells = <0>;
            bindings = <&kp LGUI>, <&kp LGUI>;
            mods = <(MOD_LALT|MOD_LCTL|MOD_LGUI|MOD_LSFT|MOD_RALT|MOD_RCTL|MOD_RGUI|MOD_RSFT)>;
            keep-mods = <(MOD_LALT|MOD_LCTL|MOD_LGUI|MOD_LSFT|MOD_RALT|MOD_RCTL|MOD_RGUI|MOD_RSFT)>;
        };

        TL6:TL6 { label = "TL6"; compatible = "zmk,behavior-mod-morph"; #binding-cells = <0>;
            bindings = <&magic 7 0>, <&magic 7 0>;
            mods = <(MOD_LALT|MOD_LCTL|MOD_LGUI|MOD_LSFT|MOD_RALT|MOD_RCTL|MOD_RGUI|MOD_RSFT)>;
            keep-mods = <(MOD_LALT|MOD_LCTL|MOD_LGUI|MOD_LSFT|MOD_RALT|MOD_RCTL|MOD_RGUI|MOD_RSFT)>;
        };

        TR1:TR1 { label = "TR1"; compatible = "zmk,behavior-mod-morph"; #binding-cells = <0>;
            bindings = <&sl 2>, <&sl 2>;
            mods = <(MOD_LALT|MOD_LCTL|MOD_LGUI|MOD_LSFT|MOD_RALT|MOD_RCTL|MOD_RGUI|MOD_RSFT)>;
            keep-mods = <(MOD_LALT|MOD_LCTL|MOD_LGUI|MOD_LSFT|MOD_RALT|MOD_RCTL|MOD_RGUI|MOD_RSFT)>;
        };

        TR2:TR2 { label = "TR2"; compatible = "zmk,behavior-mod-morph"; #binding-cells = <0>;
            bindings = <&kp DELETE>, <&kp DELETE>;
            mods = <(MOD_LALT|MOD_LCTL|MOD_LGUI|MOD_LSFT|MOD_RALT|MOD_RCTL|MOD_RGUI|MOD_RSFT)>;
            keep-mods = <(MOD_LALT|MOD_LCTL|MOD_LGUI|MOD_LSFT|MOD_RALT|MOD_RCTL|MOD_RGUI|MOD_RSFT)>;
        };

        TR3:TR3 { label = "TR3"; compatible = "zmk,behavior-mod-morph"; #binding-cells = <0>;
            bindings = <&sl 4>, <&sl 4>;
            mods = <(MOD_LALT|MOD_LCTL|MOD_LGUI|MOD_LSFT|MOD_RALT|MOD_RCTL|MOD_RGUI|MOD_RSFT)>;
            keep-mods = <(MOD_LALT|MOD_LCTL|MOD_LGUI|MOD_LSFT|MOD_RALT|MOD_RCTL|MOD_RGUI|MOD_RSFT)>;
        };

        TR4:TR4 { label = "TR4"; compatible = "zmk,behavior-mod-morph"; #binding-cells = <0>;
            bindings = <&none>, <&none>;
            mods = <(MOD_LALT|MOD_LCTL|MOD_LGUI|MOD_LSFT|MOD_RALT|MOD_RCTL|MOD_RGUI|MOD_RSFT)>;
            keep-mods = <(MOD_LALT|MOD_LCTL|MOD_LGUI|MOD_LSFT|MOD_RALT|MOD_RCTL|MOD_RGUI|MOD_RSFT)>;
        };

        TR5:TR5 { label = "TR5"; compatible = "zmk,behavior-mod-morph"; #binding-cells = <0>;
            bindings = <&kp RGUI>, <&kp RGUI>;
            mods = <(MOD_LALT|MOD_LCTL|MOD_LGUI|MOD_LSFT|MOD_RALT|MOD_RCTL|MOD_RGUI|MOD_RSFT)>;
            keep-mods = <(MOD_LALT|MOD_LCTL|MOD_LGUI|MOD_LSFT|MOD_RALT|MOD_RCTL|MOD_RGUI|MOD_RSFT)>;
        };

        TR6:TR6 { label = "TR6"; compatible = "zmk,behavior-mod-morph"; #binding-cells = <0>;
            bindings = <&magic 7 0>, <&magic 7 0>;
            mods = <(MOD_LALT|MOD_LCTL|MOD_LGUI|MOD_LSFT|MOD_RALT|MOD_RCTL|MOD_RGUI|MOD_RSFT)>;
            keep-mods = <(MOD_LALT|MOD_LCTL|MOD_LGUI|MOD_LSFT|MOD_RALT|MOD_RCTL|MOD_RGUI|MOD_RSFT)>;
        };
/*<mods-end>*/
		kp_to:kp_to {
			compatible = "zmk,behavior-macro-two-param";

			#binding-cells = <2>;
			bindings = <&macro_param_1to1 &kp MACRO_PLACEHOLDER &macro_param_2to1 &to MACRO_PLACEHOLDER>;
		label = "KP_TO";};

		kp_tog:kp_tog {
			compatible = "zmk,behavior-macro-two-param";

			#binding-cells = <2>;
			bindings = <&macro_param_1to1 &kp MACRO_PLACEHOLDER &macro_param_2to1 &tog MACRO_PLACEHOLDER>;
		label = "KP_TOG";};

		kp_sl: kp_sl {
			compatible = "zmk,behavior-macro-two-param";

			#binding-cells = <2>;
			bindings = <&macro_param_1to1 &kp MACRO_PLACEHOLDER &macro_param_2to1 &sl MACRO_PLACEHOLDER>;
		label = "KP_SL";};
    };

	//
	// Glove80 key positions index for positional hold-tap
	// - https://discord.com/channels/877392805654306816/937645688244826154/1066713913351221248
	// - https://media.discordapp.net/attachments/937645688244826154/1066713913133121556/image.png
	//
	// |------------------------|------------------------|
	// | LEFT_HAND_KEYS         |        RIGHT_HAND_KEYS |
	// |                        |                        |
	// |  0  1  2  3  4         |          5  6  7  8  9 |
	// | 10 11 12 13 14 15      |      16 17 18 19 20 21 |
	// | 22 23 24 25 26 27      |      28 29 30 31 32 33 |
	// | 34 35 36 37 38 39      |      40 41 42 43 44 45 |
	// | 46 47 48 49 50 51      |      58 59 60 61 62 63 |
	// | 64 65 66 67 68         |         75 76 77 78 79 |
	// |                69 52   |   57 74                |
	// |                 70 53  |  56 73                 |
	// |                  71 54 | 55 72                  |
	// |------------------------|------------------------|
	//

	combos {
		compatible = "zmk,combos";
/*<combos-start>*/

/*<combos-end>*/

};

};

/* Automatically generated macro definitions */

/ {
	macros {
	};
};

/* Automatically generated keymap */

/ {


behaviors {};

behaviors {};

behaviors {};

behaviors {};

behaviors {};

behaviors {};

behaviors {};

behaviors {};

behaviors {};

behaviors {};

behaviors {};

behaviors {};

behaviors {};

behaviors {};

behaviors {};

behaviors {};

behaviors {};

behaviors {};

behaviors {};

behaviors {};

behaviors {};

behaviors {};

behaviors {};

behaviors {};

behaviors {};

behaviors {};

behaviors {};

behaviors {};

behaviors {};

behaviors {};

behaviors {};

behaviors {};

behaviors {};

behaviors {};

behaviors {};

behaviors {};

behaviors {};

behaviors {};

behaviors {};

behaviors {};

behaviors {};

behaviors {};

behaviors {};

behaviors {};

behaviors {};

behaviors {};

behaviors {};
keymap {
		compatible = "zmk,keymap";
    main { // 0
    			bindings = <
&F1_key  &F2_key  &F3_key  &F4_key  &F5_key                                                          &F6_key  &F7_key  &F8_key  &F9_key  &F0_key
&K1_key  &K2_key  &K3_key  &K_key   &K5_key  &K6_key                                        &W5_key  &W6_key  &W_key   &W8_key  &W9_key  &W0_key
&G1_key  &G2_key  &G_key   &H_key   &C_key   &C6_key                                        &V5_key  &V_key   &L_key   &B_key   &B9_key  &B0_key
&O1_key  &O_key   &A_key   &I_key   &N_key   &N6_key                                        &T5_key  &T_key   &R_key   &E_key   &S_key   &S0_key
&J1_key  &J_key   &F_key   &U_key   &P_key   &P6_key  &TL2  &TL4  &TL6    &TR6  &TR4  &TR2  &M5_key  &M_key   &D_key   &Y_key   &X_key   &X0_key
&Q1_key  &Q2_key  &Q_key   &Q4_key  &Q5_key           &TL1  &TL3  &TL5    &TR5  &TR3  &TR1           &Z6_key  &Z7_key  &Z_key   &Z9_key  &Z0_key
>;};
typing { // 1
         bindings = <
&trans                   &trans                      &trans  &trans  &trans                                                                    &trans  &trans  &trans  &trans  &trans
&trans                   &trans                      &trans  &kp K   &trans  &trans                                                    &trans  &trans  &kp W   &trans  &trans  &trans
&trans                   &trans                      &kp G   &kp H   &kp C   &trans                                                    &trans  &kp V   &kp L   &kp B   &trans  &trans
&trans                   &kp O                       &kp A   &kp I   &kp N   &trans                                                    &trans  &kp T   &kp R   &kp E   &kp S   &trans
&trans                   &kp J                       &kp F   &kp U   &kp P   &trans  &trans  &trans   &trans &trans  &mo 3   &trans    &trans  &kp M   &kp D   &kp Y   &kp X   &trans
&grave_shft LSHFT GRAVE  &amp_ctrl LCTRL AMPERSAND   &kp Q   &trans  &trans          &trans  &kp LALT &trans &trans  &trans  &trans            &trans  &trans  &kp Z   &trans  &trans
>;};
upper { // 2
			bindings = <
&trans  &trans     &trans     &trans             &trans                                                                                             &trans           &trans     &trans     &trans      &trans
&trans  &trans     &trans     &kp LS(K)          &trans                 &trans                                                       &trans         &trans           &kp LS(W)  &trans     &trans      &trans
&trans  &kp GRAVE  &kp LS(G)  &kp LS(H)          &kp LS(C)              &trans                                                       &exc_equal     &kp LS(V)        &kp LS(L)  &kp LS(B)  &trans      &trans
&trans  &kp LS(O)  &kp LS(A)  &kp LS(I)          &kp LS(N)              &trans                                                       &kp ASTERISK   &kp LS(T)        &kp LS(R)  &kp LS(E)  &kp LS(S)   &trans
&trans  &kp LS(J)  &kp LS(F)  &kp LS(U)          &kp LS(P)              &kp COLON  &trans  &trans  &trans    &trans  &trans  &trans  &kp SEMICOLON  &kp LS(M)        &kp LS(D)  &kp LS(Y)  &kp LS(X)   &trans
&trans  &kp CARET  &kp LS(Q)  &kp RIGHT_BRACKET  &kp RIGHT_PARENTHESIS             &trans  &trans  &trans    &trans  &trans  &tog 2                 &kp RIGHT_BRACE  &kp CARET  &kp LS(Z)  &kp DOLLAR  &trans
>;};
nav { // 3
			bindings = <
&trans  &trans  &trans  &trans  &trans                                                                    &trans     &trans     &trans         &trans         &trans
&trans  &trans  &NAVK3  &NAVK   &NAVK5  &trans                                                    &trans  &trans     &trans     &trans         &trans         &trans
&trans  &trans  &NAVG   &NAVH   &NAVC   &trans                                                    &trans  &trans     &trans     &trans         &trans         &trans
&trans  &NAVO   &NAVA   &NAVI   &NAVN   &NAVN6                                                    &trans  &kp RCTRL  &kp RSHFT  &kp RALT       &kp RGUI       &trans
&trans  &NAVJ   &trans  &NAVU   &NAVP   &trans  &trans  &trans  &trans    &trans  &trans  &trans  &trans  &trans     &trans     &trans         &trans         &trans
&trans  &NAVQ2  &trans  &NAVQ4  &NAVQ5          &trans  &trans  &trans    &trans  &trans  &trans          &trans     &trans     &trans         &trans         &trans
>;};
num { // 4
         bindings = <
&trans  &trans  &trans  &trans  &trans                                                                                 &trans                &trans      &trans                 &trans  &trans
&trans  &trans  &NAVK3  &NAVK   &NAVK5  &trans                                                           &kp PRCNT     &kp MINUS             &kp SLASH   &kp PLUS               &trans  &trans
&trans  &trans  &NAVG   &NAVH   &NAVC   &kp BACKSPACE                                                    &kp EQUAL     &kp N7                &kp N8      &kp N9                 &trans  &trans
&trans  &NAVO   &NAVA   &NAVI   &NAVN   &kp ENTER                                                        &kp ASTERISK  &kp N4                &kp N5      &kp N6                 &kp N0  &trans
&trans  &NAVJ   &trans  &NAVU   &NAVP   &kp SPACE      &trans  &tog 4  &trans    &trans  &trans  &trans  &kp COMMA     &kp N1                &kp N2      &kp N3                 &trans  &trans
&trans  &trans  &trans  &NAVQ4  &NAVQ5                 &trans  &trans  &trans    &trans  &tog 4  &trans                &kp LEFT_PARENTHESIS  &kp PERIOD  &kp RIGHT_PARENTHESIS  &trans  &trans
>;};
ui { // 5
         bindings = <
&trans  &trans  &trans  &trans  &trans                                                                       &trans  &trans  &trans  &trans  &trans
&trans  &trans  &trans  &trans  &trans  &trans                                                       &trans  &trans  &trans  &trans  &trans  &trans
&trans  &trans  &trans  &trans  &trans  &trans                                                       &trans  &trans  &trans  &trans  &trans  &trans
&trans  &trans  &trans  &trans  &trans  &trans                                                       &trans  &trans  &trans  &trans  &trans  &trans
&trans  &trans  &trans  &trans  &trans  &trans  &trans     &trans  &trans    &trans  &trans  &trans  &trans  &trans  &trans  &trans  &trans  &trans
&trans  &trans  &trans  &trans  &trans          &kp LCTRL  &trans  &trans    &trans  &trans  &trans          &trans  &trans  &trans  &trans  &trans
>;};
gaming { // 6
         bindings = <
&kp F1        &kp F2         &kp F3  &kp F4  &kp F5                                                                                          &kp F6    &kp F7            &kp F8             &kp F9            &kp F10
&kp N6        &kp N1         &kp N2  &kp N3  &kp N4  &kp N5                                                                       &kp MINUS  &kp EQUAL &kp LEFT_BRACKET  &kp RIGHT_BRACKET  &kp F11           &kp F12
&kp N7        &kp TAB        &kp Q   &kp W   &kp E   &kp R                                                                        &kp Y      &kp U     &kp I             &kp O              &kp P             &kp BSLH
&kp N8        &kp LSHFT      &kp A   &kp S   &kp D   &kp F                                                                        &kp H      &kp J     &kp K             &kp L              &kp SEMI          &kp APOS
&kp N9        &kp LCTRL      &kp Z   &kp X   &kp C   &kp V   &kp BACKSPACE &kp ESC  &trans     &trans    &kp INSERT &kp DELETE    &kp N      &kp M     &kp UP            &kp FSLH           &kp HOME          &kp END
&kp N0        &kp ENTER      &kp T   &kp G   &kp B           &kp SPACE     &kp LALT &kp LGUI   &kp GRAVE &kp COMMA  &kp DOT                  &kp LEFT  &kp DOWN          &kp RIGHT          &kp PG_UP         &kp PAGE_DOWN
>;};
magic { // 7
		bindings = <
&none       &none            &none            &none            &none                                                                                                                 &none   &none   &none   &none  &none
&to 0       &to 1            &to 2            &to 3            &to 4            &to 5                                                                                       &none    &none   &none   &none   &none  &none
&to 6       &to 7            &NO_SET          &DE_SET          &RU_SET          &EN_SET                                                                                     &EN_SET  &RU_SET &DE_SET &NO_SET &none  &none
&none       &none            &none            &to 6            &to 1            &to 0                                                                                       &to 0    &to 1   &to 6   &none   &none  &none
&sys_reset  &rgb_ug RGB_SPI  &rgb_ug RGB_SAI  &rgb_ug RGB_HUI  &rgb_ug RGB_BRI  &rgb_ug RGB_EFF   &rgb_ug RGB_TOG &bootloader  &none            &none  &bootloader  &none   &none    &none   &none   &none   &none  &sys_reset
&bt BT_CLR  &rgb_ug RGB_SPD  &rgb_ug RGB_SAD  &rgb_ug RGB_HUD  &rgb_ug RGB_BRD                    &bt_0           &bt_1        &out OUT_USB     &none  &bt_3        &bt_2            &none   &none   &none   &none  &bt BT_CLR_ALL
>;};
	};
};
